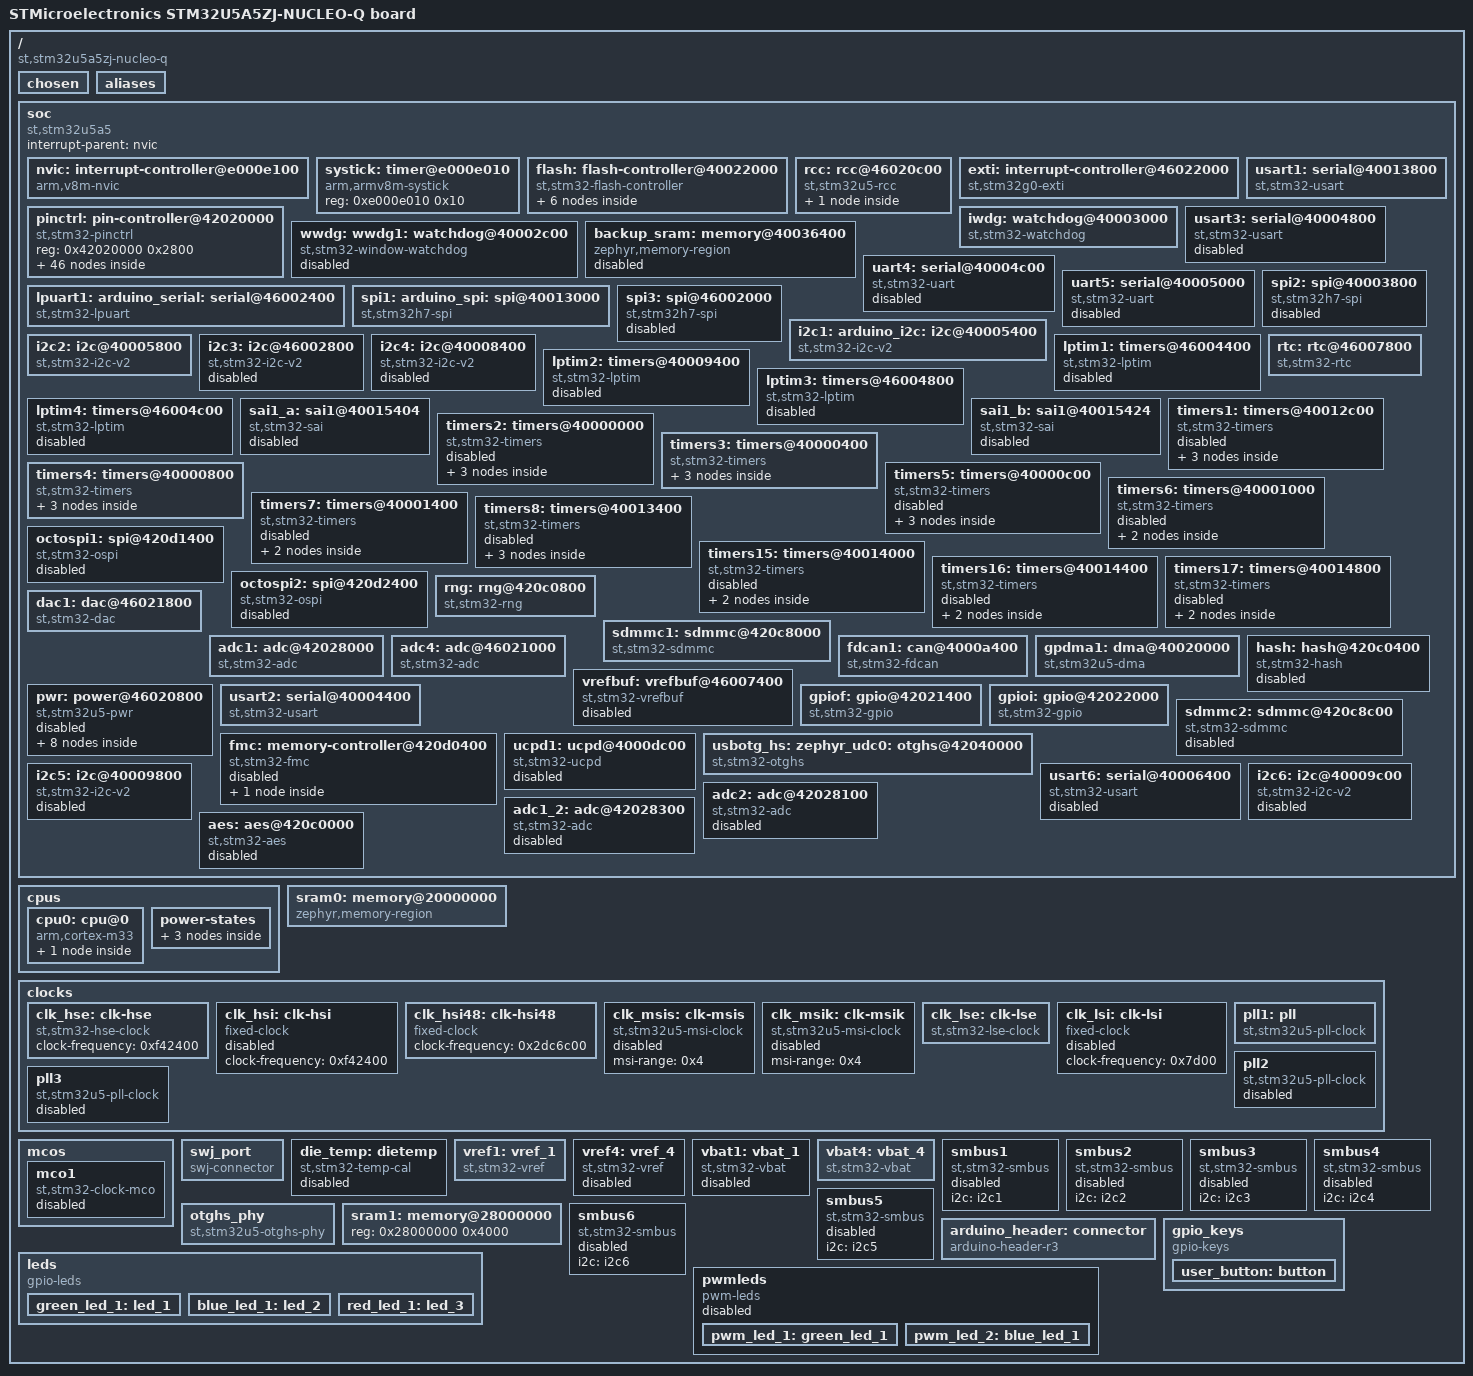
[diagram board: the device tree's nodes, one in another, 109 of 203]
/dts-v1/;

/* node '/' defined in zephyr\dts\common\skeleton.dtsi:9 */
/ {
	model = "STMicroelectronics STM32U5A5ZJ-NUCLEO-Q board"; /* in zephyr\boards\st\nucleo_u5a5zj_q\nucleo_u5a5zj_q.dts:11 */
	compatible = "st,stm32u5a5zj-nucleo-q";                  /* in zephyr\boards\st\nucleo_u5a5zj_q\nucleo_u5a5zj_q.dts:12 */
	#address-cells = < 0x1 >;                                /* in zephyr\boards\st\nucleo_u5a5zj_q\nucleo_u5a5zj_q.dts:14 */
	#size-cells = < 0x1 >;                                   /* in zephyr\boards\st\nucleo_u5a5zj_q\nucleo_u5a5zj_q.dts:15 */

	/* node '/chosen' defined in zephyr\dts\common\skeleton.dtsi:13 */
	chosen {
		zephyr,entropy = &rng;                    /* in zephyr\dts\arm\st\u5\stm32u5.dtsi:28 */
		zephyr,flash-controller = &flash;         /* in zephyr\dts\arm\st\u5\stm32u5.dtsi:29 */
		zephyr,console = &usart1;                 /* in zephyr\boards\st\nucleo_u5a5zj_q\nucleo_u5a5zj_q.dts:18 */
		zephyr,shell-uart = &usart1;              /* in zephyr\boards\st\nucleo_u5a5zj_q\nucleo_u5a5zj_q.dts:19 */
		zephyr,sram = &sram0;                     /* in zephyr\boards\st\nucleo_u5a5zj_q\nucleo_u5a5zj_q.dts:20 */
		zephyr,flash = &flash0;                   /* in zephyr\boards\st\nucleo_u5a5zj_q\nucleo_u5a5zj_q.dts:21 */
		zephyr,canbus = &fdcan1;                  /* in zephyr\boards\st\nucleo_u5a5zj_q\nucleo_u5a5zj_q.dts:22 */
		zephyr,code-partition = &slot0_partition; /* in zephyr\boards\st\nucleo_u5a5zj_q\nucleo_u5a5zj_q.dts:23 */
	};

	/* node '/aliases' defined in zephyr\dts\common\skeleton.dtsi:15 */
	aliases {
		led0 = &blue_led_1;    /* in zephyr\boards\st\nucleo_u5a5zj_q\nucleo_u5a5zj_q.dts:27 */
		sw0 = &user_button;    /* in zephyr\boards\st\nucleo_u5a5zj_q\nucleo_u5a5zj_q.dts:28 */
		pwm-led0 = &pwm_led_1; /* in zephyr\boards\st\nucleo_u5a5zj_q\nucleo_u5a5zj_q.dts:29 */
		pwm-led1 = &pwm_led_2; /* in zephyr\boards\st\nucleo_u5a5zj_q\nucleo_u5a5zj_q.dts:30 */
		watchdog0 = &iwdg;     /* in zephyr\boards\st\nucleo_u5a5zj_q\nucleo_u5a5zj_q.dts:31 */
		volt-sensor0 = &vref1; /* in zephyr\boards\st\nucleo_u5a5zj_q\nucleo_u5a5zj_q.dts:32 */
		volt-sensor1 = &vbat4; /* in zephyr\boards\st\nucleo_u5a5zj_q\nucleo_u5a5zj_q.dts:33 */
	};

	/* node '/soc' defined in zephyr\dts\arm\armv8-m.dtsi:6 */
	soc {
		#address-cells = < 0x1 >;     /* in zephyr\dts\arm\armv8-m.dtsi:7 */
		#size-cells = < 0x1 >;        /* in zephyr\dts\arm\armv8-m.dtsi:8 */
		interrupt-parent = < &nvic >; /* in zephyr\dts\arm\armv8-m.dtsi:10 */
		ranges;                       /* in zephyr\dts\arm\armv8-m.dtsi:11 */
		compatible = "st,stm32u5a5",
		             "st,stm32u5",
		             "simple-bus";    /* in zephyr\dts\arm\st\u5\stm32u5a5.dtsi:13 */

		/* node '/soc/interrupt-controller@e000e100' defined in zephyr\dts\arm\armv8-m.dtsi:13 */
		nvic: interrupt-controller@e000e100 {
			#address-cells = < 0x1 >;            /* in zephyr\dts\arm\armv8-m.dtsi:14 */
			compatible = "arm,v8m-nvic";         /* in zephyr\dts\arm\armv8-m.dtsi:15 */
			reg = < 0xe000e100 0xc00 >;          /* in zephyr\dts\arm\armv8-m.dtsi:16 */
			interrupt-controller;                /* in zephyr\dts\arm\armv8-m.dtsi:17 */
			#interrupt-cells = < 0x2 >;          /* in zephyr\dts\arm\armv8-m.dtsi:18 */
			arm,num-irq-priority-bits = < 0x4 >; /* in zephyr\dts\arm\st\u5\stm32u5.dtsi:1102 */
			phandle = < 0x1 >;                   /* in zephyr\dts\arm\armv8-m.dtsi:10 */
		};

		/* node '/soc/timer@e000e010' defined in zephyr\dts\arm\armv8-m.dtsi:21 */
		systick: timer@e000e010 {
			compatible = "arm,armv8m-systick"; /* in zephyr\dts\arm\armv8-m.dtsi:22 */
			reg = < 0xe000e010 0x10 >;         /* in zephyr\dts\arm\armv8-m.dtsi:23 */
		};

		/* node '/soc/flash-controller@40022000' defined in zephyr\dts\arm\st\u5\stm32u5.dtsi:164 */
		flash: flash-controller@40022000 {
			compatible = "st,stm32-flash-controller",
			             "st,stm32l5-flash-controller"; /* in zephyr\dts\arm\st\u5\stm32u5.dtsi:165 */
			reg = < 0x40022000 0x400 >;                 /* in zephyr\dts\arm\st\u5\stm32u5.dtsi:166 */
			interrupts = < 0x6 0x0 >;                   /* in zephyr\dts\arm\st\u5\stm32u5.dtsi:167 */
			#address-cells = < 0x1 >;                   /* in zephyr\dts\arm\st\u5\stm32u5.dtsi:169 */
			#size-cells = < 0x1 >;                      /* in zephyr\dts\arm\st\u5\stm32u5.dtsi:170 */

			/* node '/soc/flash-controller@40022000/flash@8000000' defined in zephyr\dts\arm\st\u5\stm32u5.dtsi:172 */
			flash0: flash@8000000 {
				compatible = "st,stm32-nv-flash",
				             "soc-nv-flash";      /* in zephyr\dts\arm\st\u5\stm32u5.dtsi:173 */
				write-block-size = < 0x10 >;      /* in zephyr\dts\arm\st\u5\stm32u5.dtsi:175 */
				erase-block-size = < 0x2000 >;    /* in zephyr\dts\arm\st\u5\stm32u5.dtsi:176 */
				max-erase-time = < 0x5 >;         /* in zephyr\dts\arm\st\u5\stm32u5.dtsi:178 */
				reg = < 0x8000000 0x400000 >;     /* in zephyr\dts\arm\st\u5\stm32u5a5Xj.dtsi:14 */

				/* node '/soc/flash-controller@40022000/flash@8000000/partitions' defined in zephyr\boards\st\nucleo_u5a5zj_q\nucleo_u5a5zj_q.dts:38 */
				partitions {
					compatible = "fixed-partitions"; /* in zephyr\boards\st\nucleo_u5a5zj_q\nucleo_u5a5zj_q.dts:39 */
					#address-cells = < 0x1 >;        /* in zephyr\boards\st\nucleo_u5a5zj_q\nucleo_u5a5zj_q.dts:40 */
					#size-cells = < 0x1 >;           /* in zephyr\boards\st\nucleo_u5a5zj_q\nucleo_u5a5zj_q.dts:41 */

					/* node '/soc/flash-controller@40022000/flash@8000000/partitions/partition@0' defined in zephyr\boards\st\nucleo_u5a5zj_q\nucleo_u5a5zj_q.dts:47 */
					boot_partition: partition@0 {
						label = "mcuboot";     /* in zephyr\boards\st\nucleo_u5a5zj_q\nucleo_u5a5zj_q.dts:48 */
						reg = < 0x0 0x10000 >; /* in zephyr\boards\st\nucleo_u5a5zj_q\nucleo_u5a5zj_q.dts:49 */
					};

					/* node '/soc/flash-controller@40022000/flash@8000000/partitions/partition@10000' defined in zephyr\boards\st\nucleo_u5a5zj_q\nucleo_u5a5zj_q.dts:52 */
					slot0_partition: partition@10000 {
						label = "image-0";          /* in zephyr\boards\st\nucleo_u5a5zj_q\nucleo_u5a5zj_q.dts:53 */
						reg = < 0x10000 0x1e8000 >; /* in zephyr\boards\st\nucleo_u5a5zj_q\nucleo_u5a5zj_q.dts:54 */
					};

					/* node '/soc/flash-controller@40022000/flash@8000000/partitions/partition@1f8000' defined in zephyr\boards\st\nucleo_u5a5zj_q\nucleo_u5a5zj_q.dts:57 */
					slot1_partition: partition@1f8000 {
						label = "image-1";           /* in zephyr\boards\st\nucleo_u5a5zj_q\nucleo_u5a5zj_q.dts:58 */
						reg = < 0x1f8000 0x1ea000 >; /* in zephyr\boards\st\nucleo_u5a5zj_q\nucleo_u5a5zj_q.dts:59 */
					};

					/* node '/soc/flash-controller@40022000/flash@8000000/partitions/partition@3e2000' defined in zephyr\boards\st\nucleo_u5a5zj_q\nucleo_u5a5zj_q.dts:62 */
					storage_partition: partition@3e2000 {
						label = "storage";          /* in zephyr\boards\st\nucleo_u5a5zj_q\nucleo_u5a5zj_q.dts:63 */
						reg = < 0x3e2000 0x1e000 >; /* in zephyr\boards\st\nucleo_u5a5zj_q\nucleo_u5a5zj_q.dts:64 */
					};
				};
			};
		};

		/* node '/soc/rcc@46020c00' defined in zephyr\dts\arm\st\u5\stm32u5.dtsi:182 */
		rcc: rcc@46020c00 {
			compatible = "st,stm32u5-rcc";   /* in zephyr\dts\arm\st\u5\stm32u5.dtsi:183 */
			clocks-controller;               /* in zephyr\dts\arm\st\u5\stm32u5.dtsi:184 */
			#clock-cells = < 0x2 >;          /* in zephyr\dts\arm\st\u5\stm32u5.dtsi:185 */
			reg = < 0x46020c00 0x400 >;      /* in zephyr\dts\arm\st\u5\stm32u5.dtsi:186 */
			clocks = < &pll1 >;              /* in zephyr\boards\st\nucleo_u5a5zj_q\nucleo_u5a5zj_q-common.dtsi:84 */
			clock-frequency = < 0x9896800 >; /* in zephyr\boards\st\nucleo_u5a5zj_q\nucleo_u5a5zj_q-common.dtsi:85 */
			ahb-prescaler = < 0x1 >;         /* in zephyr\boards\st\nucleo_u5a5zj_q\nucleo_u5a5zj_q-common.dtsi:86 */
			apb1-prescaler = < 0x1 >;        /* in zephyr\boards\st\nucleo_u5a5zj_q\nucleo_u5a5zj_q-common.dtsi:87 */
			apb2-prescaler = < 0x1 >;        /* in zephyr\boards\st\nucleo_u5a5zj_q\nucleo_u5a5zj_q-common.dtsi:88 */
			apb3-prescaler = < 0x1 >;        /* in zephyr\boards\st\nucleo_u5a5zj_q\nucleo_u5a5zj_q-common.dtsi:89 */
			phandle = < 0x3 >;               /* in zephyr\dts\arm\st\u5\stm32u5.dtsi:200 */

			/* node '/soc/rcc@46020c00/reset-controller' defined in zephyr\dts\arm\st\u5\stm32u5.dtsi:188 */
			rctl: reset-controller {
				compatible = "st,stm32-rcc-rctl"; /* in zephyr\dts\arm\st\u5\stm32u5.dtsi:189 */
				#reset-cells = < 0x1 >;           /* in zephyr\dts\arm\st\u5\stm32u5.dtsi:190 */
				phandle = < 0x4 >;                /* in zephyr\dts\arm\st\u5\stm32u5.dtsi:307 */
			};
		};

		/* node '/soc/interrupt-controller@46022000' defined in zephyr\dts\arm\st\u5\stm32u5.dtsi:194 */
		exti: interrupt-controller@46022000 {
			compatible = "st,stm32g0-exti",
			             "st,stm32-exti";   /* in zephyr\dts\arm\st\u5\stm32u5.dtsi:195 */
			interrupt-controller;           /* in zephyr\dts\arm\st\u5\stm32u5.dtsi:196 */
			#interrupt-cells = < 0x1 >;     /* in zephyr\dts\arm\st\u5\stm32u5.dtsi:197 */
			#address-cells = < 0x0 >;       /* in zephyr\dts\arm\st\u5\stm32u5.dtsi:198 */
			reg = < 0x46022000 0x400 >;     /* in zephyr\dts\arm\st\u5\stm32u5.dtsi:199 */
			clocks = < &rcc 0xa8 0x2 >;     /* in zephyr\dts\arm\st\u5\stm32u5.dtsi:200 */
			num-lines = < 0x20 >;           /* in zephyr\dts\arm\st\u5\stm32u5.dtsi:201 */
			interrupts = < 0xb 0x0 >,
			             < 0xc 0x0 >,
			             < 0xd 0x0 >,
			             < 0xe 0x0 >,
			             < 0xf 0x0 >,
			             < 0x10 0x0 >,
			             < 0x11 0x0 >,
			             < 0x12 0x0 >,
			             < 0x13 0x0 >,
			             < 0x14 0x0 >,
			             < 0x15 0x0 >,
			             < 0x16 0x0 >,
			             < 0x17 0x0 >,
			             < 0x18 0x0 >,
			             < 0x19 0x0 >,
			             < 0x1a 0x0 >;      /* in zephyr\dts\arm\st\u5\stm32u5.dtsi:202 */
			interrupt-names = "line0",
			                  "line1",
			                  "line2",
			                  "line3",
			                  "line4",
			                  "line5",
			                  "line6",
			                  "line7",
			                  "line8",
			                  "line9",
			                  "line10",
			                  "line11",
			                  "line12",
			                  "line13",
			                  "line14",
			                  "line15";     /* in zephyr\dts\arm\st\u5\stm32u5.dtsi:206 */
			line-ranges = < 0x0 0x1 >,
			              < 0x1 0x1 >,
			              < 0x2 0x1 >,
			              < 0x3 0x1 >,
			              < 0x4 0x1 >,
			              < 0x5 0x1 >,
			              < 0x6 0x1 >,
			              < 0x7 0x1 >,
			              < 0x8 0x1 >,
			              < 0x9 0x1 >,
			              < 0xa 0x1 >,
			              < 0xb 0x1 >,
			              < 0xc 0x1 >,
			              < 0xd 0x1 >,
			              < 0xe 0x1 >,
			              < 0xf 0x1 >;      /* in zephyr\dts\arm\st\u5\stm32u5.dtsi:210 */
		};

		/* node '/soc/pin-controller@42020000' defined in zephyr\dts\arm\st\u5\stm32u5.dtsi:216 */
		pinctrl: pin-controller@42020000 {
			compatible = "st,stm32-pinctrl"; /* in zephyr\dts\arm\st\u5\stm32u595.dtsi:26 */
			#address-cells = < 0x1 >;        /* in zephyr\dts\arm\st\u5\stm32u595.dtsi:27 */
			#size-cells = < 0x1 >;           /* in zephyr\dts\arm\st\u5\stm32u595.dtsi:28 */
			reg = < 0x42020000 0x2800 >;     /* in zephyr\dts\arm\st\u5\stm32u595.dtsi:29 */

			/* node '/soc/pin-controller@42020000/gpio@42020000' defined in zephyr\dts\arm\st\u5\stm32u5.dtsi:222 */
			gpioa: gpio@42020000 {
				compatible = "st,stm32-gpio"; /* in zephyr\dts\arm\st\u5\stm32u5.dtsi:223 */
				gpio-controller;              /* in zephyr\dts\arm\st\u5\stm32u5.dtsi:224 */
				#gpio-cells = < 0x2 >;        /* in zephyr\dts\arm\st\u5\stm32u5.dtsi:225 */
				reg = < 0x42020000 0x400 >;   /* in zephyr\dts\arm\st\u5\stm32u5.dtsi:226 */
				clocks = < &rcc 0x8c 0x1 >;   /* in zephyr\dts\arm\st\u5\stm32u5.dtsi:227 */
				phandle = < 0x1f >;           /* in zephyr\dts\arm\st\u5\stm32u5.dtsi:959 */
			};

			/* node '/soc/pin-controller@42020000/gpio@42020400' defined in zephyr\dts\arm\st\u5\stm32u5.dtsi:230 */
			gpiob: gpio@42020400 {
				compatible = "st,stm32-gpio"; /* in zephyr\dts\arm\st\u5\stm32u5.dtsi:231 */
				gpio-controller;              /* in zephyr\dts\arm\st\u5\stm32u5.dtsi:232 */
				#gpio-cells = < 0x2 >;        /* in zephyr\dts\arm\st\u5\stm32u5.dtsi:233 */
				reg = < 0x42020400 0x400 >;   /* in zephyr\dts\arm\st\u5\stm32u5.dtsi:234 */
				clocks = < &rcc 0x8c 0x2 >;   /* in zephyr\dts\arm\st\u5\stm32u5.dtsi:235 */
				phandle = < 0x20 >;           /* in zephyr\dts\arm\st\u5\stm32u5.dtsi:959 */
			};

			/* node '/soc/pin-controller@42020000/gpio@42020800' defined in zephyr\dts\arm\st\u5\stm32u5.dtsi:238 */
			gpioc: gpio@42020800 {
				compatible = "st,stm32-gpio"; /* in zephyr\dts\arm\st\u5\stm32u5.dtsi:239 */
				gpio-controller;              /* in zephyr\dts\arm\st\u5\stm32u5.dtsi:240 */
				#gpio-cells = < 0x2 >;        /* in zephyr\dts\arm\st\u5\stm32u5.dtsi:241 */
				reg = < 0x42020800 0x400 >;   /* in zephyr\dts\arm\st\u5\stm32u5.dtsi:242 */
				clocks = < &rcc 0x8c 0x4 >;   /* in zephyr\dts\arm\st\u5\stm32u5.dtsi:243 */
				phandle = < 0x22 >;           /* in zephyr\dts\arm\st\u5\stm32u5.dtsi:966 */
			};

			/* node '/soc/pin-controller@42020000/gpio@42020c00' defined in zephyr\dts\arm\st\u5\stm32u5.dtsi:246 */
			gpiod: gpio@42020c00 {
				compatible = "st,stm32-gpio"; /* in zephyr\dts\arm\st\u5\stm32u5.dtsi:247 */
				gpio-controller;              /* in zephyr\dts\arm\st\u5\stm32u5.dtsi:248 */
				#gpio-cells = < 0x2 >;        /* in zephyr\dts\arm\st\u5\stm32u5.dtsi:249 */
				reg = < 0x42020c00 0x400 >;   /* in zephyr\dts\arm\st\u5\stm32u5.dtsi:250 */
				clocks = < &rcc 0x8c 0x8 >;   /* in zephyr\dts\arm\st\u5\stm32u5.dtsi:251 */
				phandle = < 0xc >;            /* in zephyr\boards\st\nucleo_u5a5zj_q\nucleo_u5a5zj_q-common.dtsi:123 */
			};

			/* node '/soc/pin-controller@42020000/gpio@42021000' defined in zephyr\dts\arm\st\u5\stm32u5.dtsi:254 */
			gpioe: gpio@42021000 {
				compatible = "st,stm32-gpio"; /* in zephyr\dts\arm\st\u5\stm32u5.dtsi:255 */
				gpio-controller;              /* in zephyr\dts\arm\st\u5\stm32u5.dtsi:256 */
				#gpio-cells = < 0x2 >;        /* in zephyr\dts\arm\st\u5\stm32u5.dtsi:257 */
				reg = < 0x42021000 0x400 >;   /* in zephyr\dts\arm\st\u5\stm32u5.dtsi:258 */
				clocks = < &rcc 0x8c 0x10 >;  /* in zephyr\dts\arm\st\u5\stm32u5.dtsi:259 */
				phandle = < 0x21 >;           /* in zephyr\dts\arm\st\u5\stm32u5.dtsi:959 */
			};

			/* node '/soc/pin-controller@42020000/gpio@42021800' defined in zephyr\dts\arm\st\u5\stm32u5.dtsi:262 */
			gpiog: gpio@42021800 {
				compatible = "st,stm32-gpio"; /* in zephyr\dts\arm\st\u5\stm32u5.dtsi:263 */
				gpio-controller;              /* in zephyr\dts\arm\st\u5\stm32u5.dtsi:264 */
				#gpio-cells = < 0x2 >;        /* in zephyr\dts\arm\st\u5\stm32u5.dtsi:265 */
				reg = < 0x42021800 0x400 >;   /* in zephyr\dts\arm\st\u5\stm32u5.dtsi:266 */
				clocks = < &rcc 0x8c 0x40 >;  /* in zephyr\dts\arm\st\u5\stm32u5.dtsi:267 */
				phandle = < 0x3f >;           /* in zephyr\boards\st\nucleo_u5a5zj_q\arduino_r3_connector.dtsi:15 */
			};

			/* node '/soc/pin-controller@42020000/gpio@42021c00' defined in zephyr\dts\arm\st\u5\stm32u5.dtsi:270 */
			gpioh: gpio@42021c00 {
				compatible = "st,stm32-gpio"; /* in zephyr\dts\arm\st\u5\stm32u5.dtsi:271 */
				gpio-controller;              /* in zephyr\dts\arm\st\u5\stm32u5.dtsi:272 */
				#gpio-cells = < 0x2 >;        /* in zephyr\dts\arm\st\u5\stm32u5.dtsi:273 */
				reg = < 0x42021c00 0x400 >;   /* in zephyr\dts\arm\st\u5\stm32u5.dtsi:274 */
				clocks = < &rcc 0x8c 0x80 >;  /* in zephyr\dts\arm\st\u5\stm32u5.dtsi:275 */
			};

			/* node '/soc/pin-controller@42020000/gpio@42022400' defined in zephyr\dts\arm\st\u5\stm32u595.dtsi:31 */
			gpioj: gpio@42022400 {
				compatible = "st,stm32-gpio"; /* in zephyr\dts\arm\st\u5\stm32u595.dtsi:32 */
				gpio-controller;              /* in zephyr\dts\arm\st\u5\stm32u595.dtsi:33 */
				#gpio-cells = < 0x2 >;        /* in zephyr\dts\arm\st\u5\stm32u595.dtsi:34 */
				reg = < 0x42022400 0x400 >;   /* in zephyr\dts\arm\st\u5\stm32u595.dtsi:35 */
				clocks = < &rcc 0x8c 0x200 >; /* in zephyr\dts\arm\st\u5\stm32u595.dtsi:36 */
			};

			/* node '/soc/pin-controller@42020000/adc1_in1_pc0' defined in modules\hal\stm32\dts\st\u5\stm32u5a5zjtxq-pinctrl.dtsi:59 */
			adc1_in1_pc0: adc1_in1_pc0 {
				pinmux = < 0x410 >; /* in modules\hal\stm32\dts\st\u5\stm32u5a5zjtxq-pinctrl.dtsi:60 */
				phandle = < 0x1b >; /* in zephyr\boards\st\nucleo_u5a5zj_q\nucleo_u5a5zj_q-common.dtsi:134 */
			};

			/* node '/soc/pin-controller@42020000/adc4_in18_pb0' defined in modules\hal\stm32\dts\st\u5\stm32u5a5zjtxq-pinctrl.dtsi:151 */
			adc4_in18_pb0: adc4_in18_pb0 {
				pinmux = < 0x210 >; /* in modules\hal\stm32\dts\st\u5\stm32u5a5zjtxq-pinctrl.dtsi:152 */
				phandle = < 0x1c >; /* in zephyr\boards\st\nucleo_u5a5zj_q\nucleo_u5a5zj_q-common.dtsi:142 */
			};

			/* node '/soc/pin-controller@42020000/analog_pa13' defined in modules\hal\stm32\dts\st\u5\stm32u5a5zjtxq-pinctrl.dtsi:257 */
			analog_pa13: analog_pa13 {
				pinmux = < 0x1b0 >; /* in modules\hal\stm32\dts\st\u5\stm32u5a5zjtxq-pinctrl.dtsi:258 */
				phandle = < 0x32 >; /* in zephyr\dts\arm\st\u5\stm32u5.dtsi:1019 */
			};

			/* node '/soc/pin-controller@42020000/analog_pa14' defined in modules\hal\stm32\dts\st\u5\stm32u5a5zjtxq-pinctrl.dtsi:261 */
			analog_pa14: analog_pa14 {
				pinmux = < 0x1d0 >; /* in modules\hal\stm32\dts\st\u5\stm32u5a5zjtxq-pinctrl.dtsi:262 */
				phandle = < 0x33 >; /* in zephyr\dts\arm\st\u5\stm32u5.dtsi:1019 */
			};

			/* node '/soc/pin-controller@42020000/analog_pa15' defined in modules\hal\stm32\dts\st\u5\stm32u5a5zjtxq-pinctrl.dtsi:265 */
			analog_pa15: analog_pa15 {
				pinmux = < 0x1f0 >; /* in modules\hal\stm32\dts\st\u5\stm32u5a5zjtxq-pinctrl.dtsi:266 */
				phandle = < 0x34 >; /* in zephyr\dts\arm\st\u5\stm32u5.dtsi:1019 */
			};

			/* node '/soc/pin-controller@42020000/analog_pb3' defined in modules\hal\stm32\dts\st\u5\stm32u5a5zjtxq-pinctrl.dtsi:281 */
			analog_pb3: analog_pb3 {
				pinmux = < 0x270 >; /* in modules\hal\stm32\dts\st\u5\stm32u5a5zjtxq-pinctrl.dtsi:282 */
				phandle = < 0x35 >; /* in zephyr\dts\arm\st\u5\stm32u5.dtsi:1019 */
			};

			/* node '/soc/pin-controller@42020000/analog_pb4' defined in modules\hal\stm32\dts\st\u5\stm32u5a5zjtxq-pinctrl.dtsi:285 */
			analog_pb4: analog_pb4 {
				pinmux = < 0x290 >; /* in modules\hal\stm32\dts\st\u5\stm32u5a5zjtxq-pinctrl.dtsi:286 */
				phandle = < 0x36 >; /* in zephyr\dts\arm\st\u5\stm32u5.dtsi:1019 */
			};

			/* node '/soc/pin-controller@42020000/dac1_out1_pa4' defined in modules\hal\stm32\dts\st\u5\stm32u5a5zjtxq-pinctrl.dtsi:699 */
			dac1_out1_pa4: dac1_out1_pa4 {
				pinmux = < 0x90 >;  /* in modules\hal\stm32\dts\st\u5\stm32u5a5zjtxq-pinctrl.dtsi:700 */
				phandle = < 0x1a >; /* in zephyr\boards\st\nucleo_u5a5zj_q\nucleo_u5a5zj_q-common.dtsi:128 */
			};

			/* node '/soc/pin-controller@42020000/fdcan1_rx_pd0' defined in modules\hal\stm32\dts\st\u5\stm32u5a5zjtxq-pinctrl.dtsi:879 */
			fdcan1_rx_pd0: fdcan1_rx_pd0 {
				pinmux = < 0x609 >; /* in modules\hal\stm32\dts\st\u5\stm32u5a5zjtxq-pinctrl.dtsi:880 */
				phandle = < 0x1d >; /* in zephyr\boards\st\nucleo_u5a5zj_q\nucleo_u5a5zj_q-common.dtsi:182 */
			};

			/* node '/soc/pin-controller@42020000/fdcan1_tx_pd1' defined in modules\hal\stm32\dts\st\u5\stm32u5a5zjtxq-pinctrl.dtsi:897 */
			fdcan1_tx_pd1: fdcan1_tx_pd1 {
				pinmux = < 0x629 >; /* in modules\hal\stm32\dts\st\u5\stm32u5a5zjtxq-pinctrl.dtsi:898 */
				phandle = < 0x1e >; /* in zephyr\boards\st\nucleo_u5a5zj_q\nucleo_u5a5zj_q-common.dtsi:182 */
			};

			/* node '/soc/pin-controller@42020000/i2c1_scl_pb8' defined in modules\hal\stm32\dts\st\u5\stm32u5a5zjtxq-pinctrl.dtsi:1269 */
			i2c1_scl_pb8: i2c1_scl_pb8 {
				pinmux = < 0x304 >; /* in modules\hal\stm32\dts\st\u5\stm32u5a5zjtxq-pinctrl.dtsi:1270 */
				bias-pull-up;       /* in modules\hal\stm32\dts\st\u5\stm32u5a5zjtxq-pinctrl.dtsi:1271 */
				drive-open-drain;   /* in modules\hal\stm32\dts\st\u5\stm32u5a5zjtxq-pinctrl.dtsi:1272 */
				phandle = < 0xd >;  /* in zephyr\boards\st\nucleo_u5a5zj_q\nucleo_u5a5zj_q-common.dtsi:107 */
			};

			/* node '/soc/pin-controller@42020000/i2c2_scl_pf1' defined in modules\hal\stm32\dts\st\u5\stm32u5a5zjtxq-pinctrl.dtsi:1293 */
			i2c2_scl_pf1: i2c2_scl_pf1 {
				pinmux = < 0xa24 >; /* in modules\hal\stm32\dts\st\u5\stm32u5a5zjtxq-pinctrl.dtsi:1294 */
				bias-pull-up;       /* in modules\hal\stm32\dts\st\u5\stm32u5a5zjtxq-pinctrl.dtsi:1295 */
				drive-open-drain;   /* in modules\hal\stm32\dts\st\u5\stm32u5a5zjtxq-pinctrl.dtsi:1296 */
				phandle = < 0xf >;  /* in zephyr\boards\st\nucleo_u5a5zj_q\nucleo_u5a5zj_q-common.dtsi:114 */
			};

			/* node '/soc/pin-controller@42020000/i2c1_sda_pb9' defined in modules\hal\stm32\dts\st\u5\stm32u5a5zjtxq-pinctrl.dtsi:1373 */
			i2c1_sda_pb9: i2c1_sda_pb9 {
				pinmux = < 0x324 >; /* in modules\hal\stm32\dts\st\u5\stm32u5a5zjtxq-pinctrl.dtsi:1374 */
				bias-pull-up;       /* in modules\hal\stm32\dts\st\u5\stm32u5a5zjtxq-pinctrl.dtsi:1375 */
				drive-open-drain;   /* in modules\hal\stm32\dts\st\u5\stm32u5a5zjtxq-pinctrl.dtsi:1376 */
				phandle = < 0xe >;  /* in zephyr\boards\st\nucleo_u5a5zj_q\nucleo_u5a5zj_q-common.dtsi:107 */
			};

			/* node '/soc/pin-controller@42020000/i2c2_sda_pf0' defined in modules\hal\stm32\dts\st\u5\stm32u5a5zjtxq-pinctrl.dtsi:1397 */
			i2c2_sda_pf0: i2c2_sda_pf0 {
				pinmux = < 0xa04 >; /* in modules\hal\stm32\dts\st\u5\stm32u5a5zjtxq-pinctrl.dtsi:1398 */
				bias-pull-up;       /* in modules\hal\stm32\dts\st\u5\stm32u5a5zjtxq-pinctrl.dtsi:1399 */
				drive-open-drain;   /* in modules\hal\stm32\dts\st\u5\stm32u5a5zjtxq-pinctrl.dtsi:1400 */
				phandle = < 0x10 >; /* in zephyr\boards\st\nucleo_u5a5zj_q\nucleo_u5a5zj_q-common.dtsi:114 */
			};

			/* node '/soc/pin-controller@42020000/debug_jtms_swdio_pa13' defined in modules\hal\stm32\dts\st\u5\stm32u5a5zjtxq-pinctrl.dtsi:1532 */
			debug_jtms_swdio_pa13: debug_jtms_swdio_pa13 {
				pinmux = < 0x1a0 >; /* in modules\hal\stm32\dts\st\u5\stm32u5a5zjtxq-pinctrl.dtsi:1533 */
				phandle = < 0x2d >; /* in zephyr\dts\arm\st\u5\stm32u5.dtsi:1016 */
			};

			/* node '/soc/pin-controller@42020000/debug_jtck_swclk_pa14' defined in modules\hal\stm32\dts\st\u5\stm32u5a5zjtxq-pinctrl.dtsi:1536 */
			debug_jtck_swclk_pa14: debug_jtck_swclk_pa14 {
				pinmux = < 0x1c0 >; /* in modules\hal\stm32\dts\st\u5\stm32u5a5zjtxq-pinctrl.dtsi:1537 */
				phandle = < 0x2e >; /* in zephyr\dts\arm\st\u5\stm32u5.dtsi:1016 */
			};

			/* node '/soc/pin-controller@42020000/debug_jtdi_pa15' defined in modules\hal\stm32\dts\st\u5\stm32u5a5zjtxq-pinctrl.dtsi:1540 */
			debug_jtdi_pa15: debug_jtdi_pa15 {
				pinmux = < 0x1e0 >; /* in modules\hal\stm32\dts\st\u5\stm32u5a5zjtxq-pinctrl.dtsi:1541 */
				phandle = < 0x2f >; /* in zephyr\dts\arm\st\u5\stm32u5.dtsi:1016 */
			};

			/* node '/soc/pin-controller@42020000/debug_jtdo_swo_pb3' defined in modules\hal\stm32\dts\st\u5\stm32u5a5zjtxq-pinctrl.dtsi:1544 */
			debug_jtdo_swo_pb3: debug_jtdo_swo_pb3 {
				pinmux = < 0x260 >; /* in modules\hal\stm32\dts\st\u5\stm32u5a5zjtxq-pinctrl.dtsi:1545 */
				phandle = < 0x30 >; /* in zephyr\dts\arm\st\u5\stm32u5.dtsi:1016 */
			};

			/* node '/soc/pin-controller@42020000/debug_jtrst_pb4' defined in modules\hal\stm32\dts\st\u5\stm32u5a5zjtxq-pinctrl.dtsi:1548 */
			debug_jtrst_pb4: debug_jtrst_pb4 {
				pinmux = < 0x280 >; /* in modules\hal\stm32\dts\st\u5\stm32u5a5zjtxq-pinctrl.dtsi:1549 */
				phandle = < 0x31 >; /* in zephyr\dts\arm\st\u5\stm32u5.dtsi:1016 */
			};

			/* node '/soc/pin-controller@42020000/sdmmc1_d0_pc8' defined in modules\hal\stm32\dts\st\u5\stm32u5a5zjtxq-pinctrl.dtsi:2175 */
			sdmmc1_d0_pc8: sdmmc1_d0_pc8 {
				pinmux = < 0x50c >;            /* in modules\hal\stm32\dts\st\u5\stm32u5a5zjtxq-pinctrl.dtsi:2176 */
				bias-pull-up;                  /* in modules\hal\stm32\dts\st\u5\stm32u5a5zjtxq-pinctrl.dtsi:2177 */
				slew-rate = "very-high-speed"; /* in modules\hal\stm32\dts\st\u5\stm32u5a5zjtxq-pinctrl.dtsi:2178 */
				phandle = < 0x14 >;            /* in boards\nucleo_u5a5zj_q.overlay:19 */
			};

			/* node '/soc/pin-controller@42020000/sdmmc1_d1_pc9' defined in modules\hal\stm32\dts\st\u5\stm32u5a5zjtxq-pinctrl.dtsi:2181 */
			sdmmc1_d1_pc9: sdmmc1_d1_pc9 {
				pinmux = < 0x52c >;            /* in modules\hal\stm32\dts\st\u5\stm32u5a5zjtxq-pinctrl.dtsi:2182 */
				bias-pull-up;                  /* in modules\hal\stm32\dts\st\u5\stm32u5a5zjtxq-pinctrl.dtsi:2183 */
				slew-rate = "very-high-speed"; /* in modules\hal\stm32\dts\st\u5\stm32u5a5zjtxq-pinctrl.dtsi:2184 */
				phandle = < 0x15 >;            /* in boards\nucleo_u5a5zj_q.overlay:19 */
			};

			/* node '/soc/pin-controller@42020000/sdmmc1_d2_pc10' defined in modules\hal\stm32\dts\st\u5\stm32u5a5zjtxq-pinctrl.dtsi:2187 */
			sdmmc1_d2_pc10: sdmmc1_d2_pc10 {
				pinmux = < 0x54c >;            /* in modules\hal\stm32\dts\st\u5\stm32u5a5zjtxq-pinctrl.dtsi:2188 */
				bias-pull-up;                  /* in modules\hal\stm32\dts\st\u5\stm32u5a5zjtxq-pinctrl.dtsi:2189 */
				slew-rate = "very-high-speed"; /* in modules\hal\stm32\dts\st\u5\stm32u5a5zjtxq-pinctrl.dtsi:2190 */
				phandle = < 0x16 >;            /* in boards\nucleo_u5a5zj_q.overlay:19 */
			};

			/* node '/soc/pin-controller@42020000/sdmmc1_d3_pc11' defined in modules\hal\stm32\dts\st\u5\stm32u5a5zjtxq-pinctrl.dtsi:2193 */
			sdmmc1_d3_pc11: sdmmc1_d3_pc11 {
				pinmux = < 0x56c >;            /* in modules\hal\stm32\dts\st\u5\stm32u5a5zjtxq-pinctrl.dtsi:2194 */
				bias-pull-up;                  /* in modules\hal\stm32\dts\st\u5\stm32u5a5zjtxq-pinctrl.dtsi:2195 */
				slew-rate = "very-high-speed"; /* in modules\hal\stm32\dts\st\u5\stm32u5a5zjtxq-pinctrl.dtsi:2196 */
				phandle = < 0x17 >;            /* in boards\nucleo_u5a5zj_q.overlay:19 */
			};

			/* node '/soc/pin-controller@42020000/sdmmc1_ck_pc12' defined in modules\hal\stm32\dts\st\u5\stm32u5a5zjtxq-pinctrl.dtsi:2199 */
			sdmmc1_ck_pc12: sdmmc1_ck_pc12 {
				pinmux = < 0x58c >;            /* in modules\hal\stm32\dts\st\u5\stm32u5a5zjtxq-pinctrl.dtsi:2200 */
				bias-pull-up;                  /* in modules\hal\stm32\dts\st\u5\stm32u5a5zjtxq-pinctrl.dtsi:2201 */
				slew-rate = "very-high-speed"; /* in modules\hal\stm32\dts\st\u5\stm32u5a5zjtxq-pinctrl.dtsi:2202 */
				phandle = < 0x18 >;            /* in boards\nucleo_u5a5zj_q.overlay:19 */
			};

			/* node '/soc/pin-controller@42020000/sdmmc1_cmd_pd2' defined in modules\hal\stm32\dts\st\u5\stm32u5a5zjtxq-pinctrl.dtsi:2205 */
			sdmmc1_cmd_pd2: sdmmc1_cmd_pd2 {
				pinmux = < 0x64c >;            /* in modules\hal\stm32\dts\st\u5\stm32u5a5zjtxq-pinctrl.dtsi:2206 */
				bias-pull-up;                  /* in modules\hal\stm32\dts\st\u5\stm32u5a5zjtxq-pinctrl.dtsi:2207 */
				slew-rate = "very-high-speed"; /* in modules\hal\stm32\dts\st\u5\stm32u5a5zjtxq-pinctrl.dtsi:2208 */
				phandle = < 0x19 >;            /* in boards\nucleo_u5a5zj_q.overlay:19 */
			};

			/* node '/soc/pin-controller@42020000/spi1_miso_pa6' defined in modules\hal\stm32\dts\st\u5\stm32u5a5zjtxq-pinctrl.dtsi:2285 */
			spi1_miso_pa6: spi1_miso_pa6 {
				pinmux = < 0xc5 >; /* in modules\hal\stm32\dts\st\u5\stm32u5a5zjtxq-pinctrl.dtsi:2286 */
				bias-pull-down;    /* in modules\hal\stm32\dts\st\u5\stm32u5a5zjtxq-pinctrl.dtsi:2287 */
				phandle = < 0xa >; /* in zephyr\boards\st\nucleo_u5a5zj_q\nucleo_u5a5zj_q-common.dtsi:121 */
			};

			/* node '/soc/pin-controller@42020000/spi1_mosi_pa7' defined in modules\hal\stm32\dts\st\u5\stm32u5a5zjtxq-pinctrl.dtsi:2342 */
			spi1_mosi_pa7: spi1_mosi_pa7 {
				pinmux = < 0xe5 >; /* in modules\hal\stm32\dts\st\u5\stm32u5a5zjtxq-pinctrl.dtsi:2343 */
				bias-pull-down;    /* in modules\hal\stm32\dts\st\u5\stm32u5a5zjtxq-pinctrl.dtsi:2344 */
				phandle = < 0xb >; /* in zephyr\boards\st\nucleo_u5a5zj_q\nucleo_u5a5zj_q-common.dtsi:121 */
			};

			/* node '/soc/pin-controller@42020000/spi1_sck_pa5' defined in modules\hal\stm32\dts\st\u5\stm32u5a5zjtxq-pinctrl.dtsi:2462 */
			spi1_sck_pa5: spi1_sck_pa5 {
				pinmux = < 0xa5 >;             /* in modules\hal\stm32\dts\st\u5\stm32u5a5zjtxq-pinctrl.dtsi:2463 */
				bias-pull-down;                /* in modules\hal\stm32\dts\st\u5\stm32u5a5zjtxq-pinctrl.dtsi:2464 */
				slew-rate = "very-high-speed"; /* in modules\hal\stm32\dts\st\u5\stm32u5a5zjtxq-pinctrl.dtsi:2465 */
				phandle = < 0x9 >;             /* in zephyr\boards\st\nucleo_u5a5zj_q\nucleo_u5a5zj_q-common.dtsi:121 */
			};

			/* node '/soc/pin-controller@42020000/tim3_ch2_pc7' defined in modules\hal\stm32\dts\st\u5\stm32u5a5zjtxq-pinctrl.dtsi:2722 */
			tim3_ch2_pc7: tim3_ch2_pc7 {
				pinmux = < 0x4e2 >; /* in modules\hal\stm32\dts\st\u5\stm32u5a5zjtxq-pinctrl.dtsi:2723 */
				phandle = < 0x12 >; /* in zephyr\boards\st\nucleo_u5a5zj_q\nucleo_u5a5zj_q-common.dtsi:154 */
			};

			/* node '/soc/pin-controller@42020000/tim4_ch2_pb7' defined in modules\hal\stm32\dts\st\u5\stm32u5a5zjtxq-pinctrl.dtsi:2754 */
			tim4_ch2_pb7: tim4_ch2_pb7 {
				pinmux = < 0x2e2 >; /* in modules\hal\stm32\dts\st\u5\stm32u5a5zjtxq-pinctrl.dtsi:2755 */
				phandle = < 0x13 >; /* in zephyr\boards\st\nucleo_u5a5zj_q\nucleo_u5a5zj_q-common.dtsi:165 */
			};

			/* node '/soc/pin-controller@42020000/usart1_rx_pa10' defined in modules\hal\stm32\dts\st\u5\stm32u5a5zjtxq-pinctrl.dtsi:3322 */
			usart1_rx_pa10: usart1_rx_pa10 {
				pinmux = < 0x147 >; /* in modules\hal\stm32\dts\st\u5\stm32u5a5zjtxq-pinctrl.dtsi:3323 */
				phandle = < 0x6 >;  /* in zephyr\boards\st\nucleo_u5a5zj_q\nucleo_u5a5zj_q.dts:70 */
			};

			/* node '/soc/pin-controller@42020000/lpuart1_rx_pg8' defined in modules\hal\stm32\dts\st\u5\stm32u5a5zjtxq-pinctrl.dtsi:3338 */
			lpuart1_rx_pg8: lpuart1_rx_pg8 {
				pinmux = < 0xd08 >; /* in modules\hal\stm32\dts\st\u5\stm32u5a5zjtxq-pinctrl.dtsi:3339 */
				phandle = < 0x8 >;  /* in zephyr\boards\st\nucleo_u5a5zj_q\nucleo_u5a5zj_q-common.dtsi:93 */
			};

			/* node '/soc/pin-controller@42020000/usart2_rx_pd6' defined in modules\hal\stm32\dts\st\u5\stm32u5a5zjtxq-pinctrl.dtsi:3354 */
			usart2_rx_pd6: usart2_rx_pd6 {
				pinmux = < 0x6c7 >; /* in modules\hal\stm32\dts\st\u5\stm32u5a5zjtxq-pinctrl.dtsi:3355 */
				phandle = < 0x25 >; /* in zephyr\boards\st\nucleo_u5a5zj_q\nucleo_u5a5zj_q-common.dtsi:100 */
			};

			/* node '/soc/pin-controller@42020000/usart1_tx_pa9' defined in modules\hal\stm32\dts\st\u5\stm32u5a5zjtxq-pinctrl.dtsi:3413 */
			usart1_tx_pa9: usart1_tx_pa9 {
				pinmux = < 0x127 >; /* in modules\hal\stm32\dts\st\u5\stm32u5a5zjtxq-pinctrl.dtsi:3414 */
				bias-pull-up;       /* in modules\hal\stm32\dts\st\u5\stm32u5a5zjtxq-pinctrl.dtsi:3415 */
				phandle = < 0x5 >;  /* in zephyr\boards\st\nucleo_u5a5zj_q\nucleo_u5a5zj_q.dts:70 */
			};

			/* node '/soc/pin-controller@42020000/lpuart1_tx_pg7' defined in modules\hal\stm32\dts\st\u5\stm32u5a5zjtxq-pinctrl.dtsi:3433 */
			lpuart1_tx_pg7: lpuart1_tx_pg7 {
				pinmux = < 0xce8 >; /* in modules\hal\stm32\dts\st\u5\stm32u5a5zjtxq-pinctrl.dtsi:3434 */
				bias-pull-up;       /* in modules\hal\stm32\dts\st\u5\stm32u5a5zjtxq-pinctrl.dtsi:3435 */
				phandle = < 0x7 >;  /* in zephyr\boards\st\nucleo_u5a5zj_q\nucleo_u5a5zj_q-common.dtsi:93 */
			};

			/* node '/soc/pin-controller@42020000/usart2_tx_pd5' defined in modules\hal\stm32\dts\st\u5\stm32u5a5zjtxq-pinctrl.dtsi:3448 */
			usart2_tx_pd5: usart2_tx_pd5 {
				pinmux = < 0x6a7 >; /* in modules\hal\stm32\dts\st\u5\stm32u5a5zjtxq-pinctrl.dtsi:3449 */
				bias-pull-up;       /* in modules\hal\stm32\dts\st\u5\stm32u5a5zjtxq-pinctrl.dtsi:3450 */
				phandle = < 0x24 >; /* in zephyr\boards\st\nucleo_u5a5zj_q\nucleo_u5a5zj_q-common.dtsi:100 */
			};

			/* node '/soc/pin-controller@42020000/usb_otg_hs_dm_pa11' defined in modules\hal\stm32\dts\st\u5\stm32u5a5zjtxq-pinctrl.dtsi:3537 */
			usb_otg_hs_dm_pa11: usb_otg_hs_dm_pa11 {
				pinmux = < 0x170 >; /* in modules\hal\stm32\dts\st\u5\stm32u5a5zjtxq-pinctrl.dtsi:3538 */
				phandle = < 0x27 >; /* in zephyr\boards\st\nucleo_u5a5zj_q\nucleo_u5a5zj_q.dts:81 */
			};

			/* node '/soc/pin-controller@42020000/usb_otg_hs_dp_pa12' defined in modules\hal\stm32\dts\st\u5\stm32u5a5zjtxq-pinctrl.dtsi:3541 */
			usb_otg_hs_dp_pa12: usb_otg_hs_dp_pa12 {
				pinmux = < 0x190 >; /* in modules\hal\stm32\dts\st\u5\stm32u5a5zjtxq-pinctrl.dtsi:3542 */
				phandle = < 0x28 >; /* in zephyr\boards\st\nucleo_u5a5zj_q\nucleo_u5a5zj_q.dts:81 */
			};
		};

		/* node '/soc/watchdog@40003000' defined in zephyr\dts\arm\st\u5\stm32u5.dtsi:279 */
		iwdg: watchdog@40003000 {
			compatible = "st,stm32-watchdog"; /* in zephyr\dts\arm\st\u5\stm32u5.dtsi:280 */
			reg = < 0x40003000 0x400 >;       /* in zephyr\dts\arm\st\u5\stm32u5.dtsi:281 */
			interrupts = < 0x1b 0x0 >;        /* in zephyr\dts\arm\st\u5\stm32u5.dtsi:282 */
			status = "okay";                  /* in zephyr\boards\st\nucleo_u5a5zj_q\nucleo_u5a5zj_q-common.dtsi:172 */
		};

		/* node '/soc/watchdog@40002c00' defined in zephyr\dts\arm\st\u5\stm32u5.dtsi:286 */
		wwdg: wwdg1: watchdog@40002c00 {
			compatible = "st,stm32-window-watchdog"; /* in zephyr\dts\arm\st\u5\stm32u5.dtsi:287 */
			reg = < 0x40002c00 0x1000 >;             /* in zephyr\dts\arm\st\u5\stm32u5.dtsi:288 */
			clocks = < &rcc 0x9c 0x800 >;            /* in zephyr\dts\arm\st\u5\stm32u5.dtsi:289 */
			interrupts = < 0x0 0x7 >;                /* in zephyr\dts\arm\st\u5\stm32u5.dtsi:290 */
			status = "disabled";                     /* in zephyr\dts\arm\st\u5\stm32u5.dtsi:291 */
		};

		/* node '/soc/memory@40036400' defined in zephyr\dts\arm\st\u5\stm32u5.dtsi:294 */
		backup_sram: memory@40036400 {
			compatible = "zephyr,memory-region",
			             "st,stm32-backup-sram";  /* in zephyr\dts\arm\st\u5\stm32u5.dtsi:295 */
			reg = < 0x40036400 0x800 >;           /* in zephyr\dts\arm\st\u5\stm32u5.dtsi:296 */
			clocks = < &rcc 0x88 0x10020000 >;    /* in zephyr\dts\arm\st\u5\stm32u5.dtsi:298 */
			zephyr,memory-region = "BACKUP_SRAM"; /* in zephyr\dts\arm\st\u5\stm32u5.dtsi:299 */
			status = "disabled";                  /* in zephyr\dts\arm\st\u5\stm32u5.dtsi:300 */
		};

		/* node '/soc/serial@40013800' defined in zephyr\dts\arm\st\u5\stm32u5.dtsi:303 */
		usart1: serial@40013800 {
			compatible = "st,stm32-usart",
			             "st,stm32-uart";                   /* in zephyr\dts\arm\st\u5\stm32u5.dtsi:304 */
			reg = < 0x40013800 0x400 >;                     /* in zephyr\dts\arm\st\u5\stm32u5.dtsi:305 */
			clocks = < &rcc 0xa4 0x4000 >;                  /* in zephyr\dts\arm\st\u5\stm32u5.dtsi:306 */
			resets = < &rctl 0xf8e >;                       /* in zephyr\dts\arm\st\u5\stm32u5.dtsi:307 */
			interrupts = < 0x3d 0x0 >;                      /* in zephyr\dts\arm\st\u5\stm32u5.dtsi:308 */
			pinctrl-0 = < &usart1_tx_pa9 &usart1_rx_pa10 >; /* in zephyr\boards\st\nucleo_u5a5zj_q\nucleo_u5a5zj_q.dts:70 */
			pinctrl-names = "default";                      /* in zephyr\boards\st\nucleo_u5a5zj_q\nucleo_u5a5zj_q.dts:71 */
			current-speed = < 0x1c200 >;                    /* in zephyr\boards\st\nucleo_u5a5zj_q\nucleo_u5a5zj_q.dts:72 */
			status = "okay";                                /* in zephyr\boards\st\nucleo_u5a5zj_q\nucleo_u5a5zj_q.dts:73 */
		};

		/* node '/soc/serial@40004800' defined in zephyr\dts\arm\st\u5\stm32u5.dtsi:312 */
		usart3: serial@40004800 {
			compatible = "st,stm32-usart",
			             "st,stm32-uart";   /* in zephyr\dts\arm\st\u5\stm32u5.dtsi:313 */
			reg = < 0x40004800 0x400 >;     /* in zephyr\dts\arm\st\u5\stm32u5.dtsi:314 */
			clocks = < &rcc 0x9c 0x40000 >; /* in zephyr\dts\arm\st\u5\stm32u5.dtsi:315 */
			resets = < &rctl 0xe92 >;       /* in zephyr\dts\arm\st\u5\stm32u5.dtsi:316 */
			interrupts = < 0x3f 0x0 >;      /* in zephyr\dts\arm\st\u5\stm32u5.dtsi:317 */
			status = "disabled";            /* in zephyr\dts\arm\st\u5\stm32u5.dtsi:318 */
		};

		/* node '/soc/serial@40004c00' defined in zephyr\dts\arm\st\u5\stm32u5.dtsi:321 */
		uart4: serial@40004c00 {
			compatible = "st,stm32-uart";   /* in zephyr\dts\arm\st\u5\stm32u5.dtsi:322 */
			reg = < 0x40004c00 0x400 >;     /* in zephyr\dts\arm\st\u5\stm32u5.dtsi:323 */
			clocks = < &rcc 0x9c 0x80000 >; /* in zephyr\dts\arm\st\u5\stm32u5.dtsi:324 */
			resets = < &rctl 0xe93 >;       /* in zephyr\dts\arm\st\u5\stm32u5.dtsi:325 */
			interrupts = < 0x40 0x0 >;      /* in zephyr\dts\arm\st\u5\stm32u5.dtsi:326 */
			status = "disabled";            /* in zephyr\dts\arm\st\u5\stm32u5.dtsi:327 */
		};

		/* node '/soc/serial@40005000' defined in zephyr\dts\arm\st\u5\stm32u5.dtsi:330 */
		uart5: serial@40005000 {
			compatible = "st,stm32-uart";    /* in zephyr\dts\arm\st\u5\stm32u5.dtsi:331 */
			reg = < 0x40005000 0x400 >;      /* in zephyr\dts\arm\st\u5\stm32u5.dtsi:332 */
			clocks = < &rcc 0x9c 0x100000 >; /* in zephyr\dts\arm\st\u5\stm32u5.dtsi:333 */
			resets = < &rctl 0xe94 >;        /* in zephyr\dts\arm\st\u5\stm32u5.dtsi:334 */
			interrupts = < 0x41 0x0 >;       /* in zephyr\dts\arm\st\u5\stm32u5.dtsi:335 */
			status = "disabled";             /* in zephyr\dts\arm\st\u5\stm32u5.dtsi:336 */
		};

		/* node '/soc/serial@46002400' defined in zephyr\dts\arm\st\u5\stm32u5.dtsi:339 */
		lpuart1: arduino_serial: serial@46002400 {
			compatible = "st,stm32-lpuart",
			             "st,stm32-uart";                    /* in zephyr\dts\arm\st\u5\stm32u5.dtsi:340 */
			reg = < 0x46002400 0x400 >;                      /* in zephyr\dts\arm\st\u5\stm32u5.dtsi:341 */
			clocks = < &rcc 0xa8 0x40 >;                     /* in zephyr\dts\arm\st\u5\stm32u5.dtsi:342 */
			resets = < &rctl 0x1006 >;                       /* in zephyr\dts\arm\st\u5\stm32u5.dtsi:343 */
			interrupts = < 0x42 0x0 >;                       /* in zephyr\dts\arm\st\u5\stm32u5.dtsi:344 */
			pinctrl-0 = < &lpuart1_tx_pg7 &lpuart1_rx_pg8 >; /* in zephyr\boards\st\nucleo_u5a5zj_q\nucleo_u5a5zj_q-common.dtsi:93 */
			pinctrl-names = "default";                       /* in zephyr\boards\st\nucleo_u5a5zj_q\nucleo_u5a5zj_q-common.dtsi:94 */
			current-speed = < 0x1c200 >;                     /* in zephyr\boards\st\nucleo_u5a5zj_q\nucleo_u5a5zj_q-common.dtsi:95 */
			status = "okay";                                 /* in zephyr\boards\st\nucleo_u5a5zj_q\nucleo_u5a5zj_q-common.dtsi:96 */
		};

		/* node '/soc/spi@40013000' defined in zephyr\dts\arm\st\u5\stm32u5.dtsi:348 */
		spi1: arduino_spi: spi@40013000 {
			compatible = "st,stm32h7-spi",
			             "st,stm32-spi-fifo",
			             "st,stm32-spi";                                 /* in zephyr\dts\arm\st\u5\stm32u5.dtsi:349 */
			#address-cells = < 0x1 >;                                    /* in zephyr\dts\arm\st\u5\stm32u5.dtsi:350 */
			#size-cells = < 0x0 >;                                       /* in zephyr\dts\arm\st\u5\stm32u5.dtsi:351 */
			reg = < 0x40013000 0x400 >;                                  /* in zephyr\dts\arm\st\u5\stm32u5.dtsi:352 */
			interrupts = < 0x3b 0x5 >;                                   /* in zephyr\dts\arm\st\u5\stm32u5.dtsi:353 */
			clocks = < &rcc 0xa4 0x1000 >;                               /* in zephyr\dts\arm\st\u5\stm32u5.dtsi:354 */
			st,spi-data-width = "full-4-to-32-bit";                      /* in zephyr\dts\arm\st\u5\stm32u5.dtsi:355 */
			pinctrl-0 = < &spi1_sck_pa5 &spi1_miso_pa6 &spi1_mosi_pa7 >; /* in zephyr\boards\st\nucleo_u5a5zj_q\nucleo_u5a5zj_q-common.dtsi:121 */
			pinctrl-names = "default";                                   /* in zephyr\boards\st\nucleo_u5a5zj_q\nucleo_u5a5zj_q-common.dtsi:122 */
			cs-gpios = < &gpiod 0xe 0x1 >;                               /* in zephyr\boards\st\nucleo_u5a5zj_q\nucleo_u5a5zj_q-common.dtsi:123 */
			status = "okay";                                             /* in zephyr\boards\st\nucleo_u5a5zj_q\nucleo_u5a5zj_q-common.dtsi:124 */
		};

		/* node '/soc/spi@40003800' defined in zephyr\dts\arm\st\u5\stm32u5.dtsi:359 */
		spi2: spi@40003800 {
			compatible = "st,stm32h7-spi",
			             "st,stm32-spi-fifo",
			             "st,stm32-spi";            /* in zephyr\dts\arm\st\u5\stm32u5.dtsi:360 */
			#address-cells = < 0x1 >;               /* in zephyr\dts\arm\st\u5\stm32u5.dtsi:361 */
			#size-cells = < 0x0 >;                  /* in zephyr\dts\arm\st\u5\stm32u5.dtsi:362 */
			reg = < 0x40003800 0x400 >;             /* in zephyr\dts\arm\st\u5\stm32u5.dtsi:363 */
			interrupts = < 0x3c 0x5 >;              /* in zephyr\dts\arm\st\u5\stm32u5.dtsi:364 */
			clocks = < &rcc 0x9c 0x4000 >;          /* in zephyr\dts\arm\st\u5\stm32u5.dtsi:365 */
			st,spi-data-width = "full-4-to-32-bit"; /* in zephyr\dts\arm\st\u5\stm32u5.dtsi:366 */
			status = "disabled";                    /* in zephyr\dts\arm\st\u5\stm32u5.dtsi:367 */
		};

		/* node '/soc/spi@46002000' defined in zephyr\dts\arm\st\u5\stm32u5.dtsi:370 */
		spi3: spi@46002000 {
			compatible = "st,stm32h7-spi",
			             "st,stm32-spi-fifo",
			             "st,stm32-spi";            /* in zephyr\dts\arm\st\u5\stm32u5.dtsi:371 */
			#address-cells = < 0x1 >;               /* in zephyr\dts\arm\st\u5\stm32u5.dtsi:372 */
			#size-cells = < 0x0 >;                  /* in zephyr\dts\arm\st\u5\stm32u5.dtsi:373 */
			reg = < 0x46002000 0x400 >;             /* in zephyr\dts\arm\st\u5\stm32u5.dtsi:374 */
			interrupts = < 0x63 0x5 >;              /* in zephyr\dts\arm\st\u5\stm32u5.dtsi:375 */
			clocks = < &rcc 0xa8 0x20 >;            /* in zephyr\dts\arm\st\u5\stm32u5.dtsi:376 */
			st,spi-data-width = "limited-8-16-bit"; /* in zephyr\dts\arm\st\u5\stm32u5.dtsi:377 */
			status = "disabled";                    /* in zephyr\dts\arm\st\u5\stm32u5.dtsi:378 */
		};

		/* node '/soc/i2c@40005400' defined in zephyr\dts\arm\st\u5\stm32u5.dtsi:381 */
		i2c1: arduino_i2c: i2c@40005400 {
			compatible = "st,stm32-i2c-v2";              /* in zephyr\dts\arm\st\u5\stm32u5.dtsi:382 */
			#address-cells = < 0x1 >;                    /* in zephyr\dts\arm\st\u5\stm32u5.dtsi:384 */
			#size-cells = < 0x0 >;                       /* in zephyr\dts\arm\st\u5\stm32u5.dtsi:385 */
			reg = < 0x40005400 0x400 >;                  /* in zephyr\dts\arm\st\u5\stm32u5.dtsi:386 */
			clocks = < &rcc 0x9c 0x200000 >;             /* in zephyr\dts\arm\st\u5\stm32u5.dtsi:387 */
			interrupts = < 0x37 0x0 >,
			             < 0x38 0x0 >;                   /* in zephyr\dts\arm\st\u5\stm32u5.dtsi:388 */
			interrupt-names = "event",
			                  "error";                   /* in zephyr\dts\arm\st\u5\stm32u5.dtsi:389 */
			pinctrl-0 = < &i2c1_scl_pb8 &i2c1_sda_pb9 >; /* in zephyr\boards\st\nucleo_u5a5zj_q\nucleo_u5a5zj_q-common.dtsi:107 */
			pinctrl-names = "default";                   /* in zephyr\boards\st\nucleo_u5a5zj_q\nucleo_u5a5zj_q-common.dtsi:108 */
			status = "okay";                             /* in zephyr\boards\st\nucleo_u5a5zj_q\nucleo_u5a5zj_q-common.dtsi:109 */
			clock-frequency = < 0x61a80 >;               /* in zephyr\boards\st\nucleo_u5a5zj_q\nucleo_u5a5zj_q-common.dtsi:110 */
			phandle = < 0x39 >;                          /* in zephyr\dts\arm\st\u5\stm32u5.dtsi:1072 */
		};

		/* node '/soc/i2c@40005800' defined in zephyr\dts\arm\st\u5\stm32u5.dtsi:393 */
		i2c2: i2c@40005800 {
			compatible = "st,stm32-i2c-v2";              /* in zephyr\dts\arm\st\u5\stm32u5.dtsi:394 */
			#address-cells = < 0x1 >;                    /* in zephyr\dts\arm\st\u5\stm32u5.dtsi:396 */
			#size-cells = < 0x0 >;                       /* in zephyr\dts\arm\st\u5\stm32u5.dtsi:397 */
			reg = < 0x40005800 0x400 >;                  /* in zephyr\dts\arm\st\u5\stm32u5.dtsi:398 */
			clocks = < &rcc 0x9c 0x400000 >;             /* in zephyr\dts\arm\st\u5\stm32u5.dtsi:399 */
			interrupts = < 0x39 0x0 >,
			             < 0x3a 0x0 >;                   /* in zephyr\dts\arm\st\u5\stm32u5.dtsi:400 */
			interrupt-names = "event",
			                  "error";                   /* in zephyr\dts\arm\st\u5\stm32u5.dtsi:401 */
			pinctrl-0 = < &i2c2_scl_pf1 &i2c2_sda_pf0 >; /* in zephyr\boards\st\nucleo_u5a5zj_q\nucleo_u5a5zj_q-common.dtsi:114 */
			pinctrl-names = "default";                   /* in zephyr\boards\st\nucleo_u5a5zj_q\nucleo_u5a5zj_q-common.dtsi:115 */
			status = "okay";                             /* in zephyr\boards\st\nucleo_u5a5zj_q\nucleo_u5a5zj_q-common.dtsi:116 */
			clock-frequency = < 0x61a80 >;               /* in zephyr\boards\st\nucleo_u5a5zj_q\nucleo_u5a5zj_q-common.dtsi:117 */
			phandle = < 0x3a >;                          /* in zephyr\dts\arm\st\u5\stm32u5.dtsi:1080 */
		};

		/* node '/soc/i2c@46002800' defined in zephyr\dts\arm\st\u5\stm32u5.dtsi:405 */
		i2c3: i2c@46002800 {
			compatible = "st,stm32-i2c-v2"; /* in zephyr\dts\arm\st\u5\stm32u5.dtsi:406 */
			clock-frequency = < 0x186a0 >;  /* in zephyr\dts\arm\st\u5\stm32u5.dtsi:407 */
			#address-cells = < 0x1 >;       /* in zephyr\dts\arm\st\u5\stm32u5.dtsi:408 */
			#size-cells = < 0x0 >;          /* in zephyr\dts\arm\st\u5\stm32u5.dtsi:409 */
			reg = < 0x46002800 0x400 >;     /* in zephyr\dts\arm\st\u5\stm32u5.dtsi:410 */
			clocks = < &rcc 0xa8 0x80 >;    /* in zephyr\dts\arm\st\u5\stm32u5.dtsi:411 */
			interrupts = < 0x58 0x0 >,
			             < 0x59 0x0 >;      /* in zephyr\dts\arm\st\u5\stm32u5.dtsi:412 */
			interrupt-names = "event",
			                  "error";      /* in zephyr\dts\arm\st\u5\stm32u5.dtsi:413 */
			status = "disabled";            /* in zephyr\dts\arm\st\u5\stm32u5.dtsi:414 */
			phandle = < 0x3b >;             /* in zephyr\dts\arm\st\u5\stm32u5.dtsi:1088 */
		};

		/* node '/soc/i2c@40008400' defined in zephyr\dts\arm\st\u5\stm32u5.dtsi:417 */
		i2c4: i2c@40008400 {
			compatible = "st,stm32-i2c-v2"; /* in zephyr\dts\arm\st\u5\stm32u5.dtsi:418 */
			clock-frequency = < 0x186a0 >;  /* in zephyr\dts\arm\st\u5\stm32u5.dtsi:419 */
			#address-cells = < 0x1 >;       /* in zephyr\dts\arm\st\u5\stm32u5.dtsi:420 */
			#size-cells = < 0x0 >;          /* in zephyr\dts\arm\st\u5\stm32u5.dtsi:421 */
			reg = < 0x40008400 0x400 >;     /* in zephyr\dts\arm\st\u5\stm32u5.dtsi:422 */
			clocks = < &rcc 0xa0 0x2 >;     /* in zephyr\dts\arm\st\u5\stm32u5.dtsi:423 */
			interrupts = < 0x65 0x0 >,
			             < 0x64 0x0 >;      /* in zephyr\dts\arm\st\u5\stm32u5.dtsi:424 */
			interrupt-names = "event",
			                  "error";      /* in zephyr\dts\arm\st\u5\stm32u5.dtsi:425 */
			status = "disabled";            /* in zephyr\dts\arm\st\u5\stm32u5.dtsi:426 */
			phandle = < 0x3c >;             /* in zephyr\dts\arm\st\u5\stm32u5.dtsi:1096 */
		};

		/* node '/soc/timers@46004400' defined in zephyr\dts\arm\st\u5\stm32u5.dtsi:429 */
		lptim1: timers@46004400 {
			compatible = "st,stm32-lptim"; /* in zephyr\dts\arm\st\u5\stm32u5.dtsi:430 */
			#address-cells = < 0x1 >;      /* in zephyr\dts\arm\st\u5\stm32u5.dtsi:431 */
			#size-cells = < 0x0 >;         /* in zephyr\dts\arm\st\u5\stm32u5.dtsi:432 */
			reg = < 0x46004400 0x400 >;    /* in zephyr\dts\arm\st\u5\stm32u5.dtsi:433 */
			clocks = < &rcc 0xa8 0x800 >;  /* in zephyr\dts\arm\st\u5\stm32u5.dtsi:434 */
			resets = < &rctl 0x100b >;     /* in zephyr\dts\arm\st\u5\stm32u5.dtsi:435 */
			interrupts = < 0x43 0x1 >;     /* in zephyr\dts\arm\st\u5\stm32u5.dtsi:436 */
			interrupt-names = "wakeup";    /* in zephyr\dts\arm\st\u5\stm32u5.dtsi:437 */
			status = "disabled";           /* in zephyr\dts\arm\st\u5\stm32u5.dtsi:438 */
		};

		/* node '/soc/timers@40009400' defined in zephyr\dts\arm\st\u5\stm32u5.dtsi:441 */
		lptim2: timers@40009400 {
			compatible = "st,stm32-lptim"; /* in zephyr\dts\arm\st\u5\stm32u5.dtsi:442 */
			#address-cells = < 0x1 >;      /* in zephyr\dts\arm\st\u5\stm32u5.dtsi:443 */
			#size-cells = < 0x0 >;         /* in zephyr\dts\arm\st\u5\stm32u5.dtsi:444 */
			reg = < 0x40009400 0x400 >;    /* in zephyr\dts\arm\st\u5\stm32u5.dtsi:445 */
			clocks = < &rcc 0xa0 0x20 >;   /* in zephyr\dts\arm\st\u5\stm32u5.dtsi:446 */
			resets = < &rctl 0xf05 >;      /* in zephyr\dts\arm\st\u5\stm32u5.dtsi:447 */
			interrupts = < 0x44 0x0 >;     /* in zephyr\dts\arm\st\u5\stm32u5.dtsi:448 */
			interrupt-names = "global";    /* in zephyr\dts\arm\st\u5\stm32u5.dtsi:449 */
			status = "disabled";           /* in zephyr\dts\arm\st\u5\stm32u5.dtsi:450 */
		};

		/* node '/soc/timers@46004800' defined in zephyr\dts\arm\st\u5\stm32u5.dtsi:453 */
		lptim3: timers@46004800 {
			compatible = "st,stm32-lptim"; /* in zephyr\dts\arm\st\u5\stm32u5.dtsi:454 */
			#address-cells = < 0x1 >;      /* in zephyr\dts\arm\st\u5\stm32u5.dtsi:455 */
			#size-cells = < 0x0 >;         /* in zephyr\dts\arm\st\u5\stm32u5.dtsi:456 */
			reg = < 0x46004800 0x400 >;    /* in zephyr\dts\arm\st\u5\stm32u5.dtsi:457 */
			clocks = < &rcc 0xa8 0x1000 >; /* in zephyr\dts\arm\st\u5\stm32u5.dtsi:458 */
			resets = < &rctl 0x100c >;     /* in zephyr\dts\arm\st\u5\stm32u5.dtsi:459 */
			interrupts = < 0x62 0x0 >;     /* in zephyr\dts\arm\st\u5\stm32u5.dtsi:460 */
			interrupt-names = "global";    /* in zephyr\dts\arm\st\u5\stm32u5.dtsi:461 */
			status = "disabled";           /* in zephyr\dts\arm\st\u5\stm32u5.dtsi:462 */
		};

		/* node '/soc/timers@46004c00' defined in zephyr\dts\arm\st\u5\stm32u5.dtsi:465 */
		lptim4: timers@46004c00 {
			compatible = "st,stm32-lptim"; /* in zephyr\dts\arm\st\u5\stm32u5.dtsi:466 */
			#address-cells = < 0x1 >;      /* in zephyr\dts\arm\st\u5\stm32u5.dtsi:467 */
			#size-cells = < 0x0 >;         /* in zephyr\dts\arm\st\u5\stm32u5.dtsi:468 */
			reg = < 0x46004c00 0x400 >;    /* in zephyr\dts\arm\st\u5\stm32u5.dtsi:469 */
			clocks = < &rcc 0xa8 0x2000 >; /* in zephyr\dts\arm\st\u5\stm32u5.dtsi:470 */
			resets = < &rctl 0x100d >;     /* in zephyr\dts\arm\st\u5\stm32u5.dtsi:471 */
			interrupts = < 0x6e 0x0 >;     /* in zephyr\dts\arm\st\u5\stm32u5.dtsi:472 */
			interrupt-names = "global";    /* in zephyr\dts\arm\st\u5\stm32u5.dtsi:473 */
			status = "disabled";           /* in zephyr\dts\arm\st\u5\stm32u5.dtsi:474 */
		};

		/* node '/soc/rtc@46007800' defined in zephyr\dts\arm\st\u5\stm32u5.dtsi:477 */
		rtc: rtc@46007800 {
			compatible = "st,stm32-rtc";     /* in zephyr\dts\arm\st\u5\stm32u5.dtsi:478 */
			reg = < 0x46007800 0x400 >;      /* in zephyr\dts\arm\st\u5\stm32u5.dtsi:479 */
			interrupts = < 0x2 0x0 >;        /* in zephyr\dts\arm\st\u5\stm32u5.dtsi:480 */
			prescaler = < 0x8000 >;          /* in zephyr\dts\arm\st\u5\stm32u5.dtsi:482 */
			alarms-count = < 0x2 >;          /* in zephyr\dts\arm\st\u5\stm32u5.dtsi:483 */
			clocks = < &rcc 0xa8 0x200000 >,
			         < &rcc 0x2 0x12800f0 >; /* in zephyr\boards\st\nucleo_u5a5zj_q\nucleo_u5a5zj_q-common.dtsi:188 */
			status = "okay";                 /* in zephyr\boards\st\nucleo_u5a5zj_q\nucleo_u5a5zj_q-common.dtsi:190 */
		};

		/* node '/soc/sai1@40015404' defined in zephyr\dts\arm\st\u5\stm32u5.dtsi:487 */
		sai1_a: sai1@40015404 {
			compatible = "st,stm32-sai";         /* in zephyr\dts\arm\st\u5\stm32u5.dtsi:488 */
			#address-cells = < 0x1 >;            /* in zephyr\dts\arm\st\u5\stm32u5.dtsi:489 */
			#size-cells = < 0x0 >;               /* in zephyr\dts\arm\st\u5\stm32u5.dtsi:490 */
			reg = < 0x40015404 0x20 >;           /* in zephyr\dts\arm\st\u5\stm32u5.dtsi:491 */
			clocks = < &rcc 0xa4 0x200000 >,
			         < &rcc 0x12 0x4500e4 >;     /* in zephyr\dts\arm\st\u5\stm32u5.dtsi:492 */
			dmas = < &gpdma1 0x1 0x24 0x22800 >; /* in zephyr\dts\arm\st\u5\stm32u5.dtsi:494 */
			status = "disabled";                 /* in zephyr\dts\arm\st\u5\stm32u5.dtsi:496 */
		};

		/* node '/soc/sai1@40015424' defined in zephyr\dts\arm\st\u5\stm32u5.dtsi:499 */
		sai1_b: sai1@40015424 {
			compatible = "st,stm32-sai";         /* in zephyr\dts\arm\st\u5\stm32u5.dtsi:500 */
			#address-cells = < 0x1 >;            /* in zephyr\dts\arm\st\u5\stm32u5.dtsi:501 */
			#size-cells = < 0x0 >;               /* in zephyr\dts\arm\st\u5\stm32u5.dtsi:502 */
			reg = < 0x40015424 0x20 >;           /* in zephyr\dts\arm\st\u5\stm32u5.dtsi:503 */
			clocks = < &rcc 0xa4 0x200000 >,
			         < &rcc 0x12 0x4500e4 >;     /* in zephyr\dts\arm\st\u5\stm32u5.dtsi:504 */
			dmas = < &gpdma1 0x0 0x25 0x22800 >; /* in zephyr\dts\arm\st\u5\stm32u5.dtsi:506 */
			status = "disabled";                 /* in zephyr\dts\arm\st\u5\stm32u5.dtsi:508 */
		};

		/* node '/soc/timers@40012c00' defined in zephyr\dts\arm\st\u5\stm32u5.dtsi:511 */
		timers1: timers@40012c00 {
			compatible = "st,stm32-timers"; /* in zephyr\dts\arm\st\u5\stm32u5.dtsi:512 */
			reg = < 0x40012c00 0x400 >;     /* in zephyr\dts\arm\st\u5\stm32u5.dtsi:513 */
			clocks = < &rcc 0xa4 0x800 >,
			         < &rcc 0xe 0xff >;     /* in zephyr\dts\arm\st\u5\stm32u5.dtsi:514 */
			resets = < &rctl 0xf8b >;       /* in zephyr\dts\arm\st\u5\stm32u5.dtsi:516 */
			interrupts = < 0x29 0x0 >,
			             < 0x2a 0x0 >,
			             < 0x2b 0x0 >,
			             < 0x2c 0x0 >;      /* in zephyr\dts\arm\st\u5\stm32u5.dtsi:517 */
			interrupt-names = "brk",
			                  "up",
			                  "trgcom",
			                  "cc";         /* in zephyr\dts\arm\st\u5\stm32u5.dtsi:518 */
			status = "disabled";            /* in zephyr\dts\arm\st\u5\stm32u5.dtsi:519 */

			/* node '/soc/timers@40012c00/pwm' defined in zephyr\dts\arm\st\u5\stm32u5.dtsi:521 */
			pwm {
				compatible = "st,stm32-pwm"; /* in zephyr\dts\arm\st\u5\stm32u5.dtsi:522 */
				status = "disabled";         /* in zephyr\dts\arm\st\u5\stm32u5.dtsi:523 */
				#pwm-cells = < 0x3 >;        /* in zephyr\dts\arm\st\u5\stm32u5.dtsi:524 */
			};

			/* node '/soc/timers@40012c00/counter' defined in zephyr\dts\arm\st\u5\stm32u5.dtsi:527 */
			counter {
				compatible = "st,stm32-counter"; /* in zephyr\dts\arm\st\u5\stm32u5.dtsi:528 */
				status = "disabled";             /* in zephyr\dts\arm\st\u5\stm32u5.dtsi:529 */
			};

			/* node '/soc/timers@40012c00/qdec' defined in zephyr\dts\arm\st\u5\stm32u5.dtsi:532 */
			qdec {
				compatible = "st,stm32-qdec";    /* in zephyr\dts\arm\st\u5\stm32u5.dtsi:533 */
				st,input-filter-level = < 0x0 >; /* in zephyr\dts\arm\st\u5\stm32u5.dtsi:534 */
				status = "disabled";             /* in zephyr\dts\arm\st\u5\stm32u5.dtsi:535 */
			};
		};

		/* node '/soc/timers@40000000' defined in zephyr\dts\arm\st\u5\stm32u5.dtsi:539 */
		timers2: timers@40000000 {
			compatible = "st,stm32-timers"; /* in zephyr\dts\arm\st\u5\stm32u5.dtsi:540 */
			reg = < 0x40000000 0x400 >;     /* in zephyr\dts\arm\st\u5\stm32u5.dtsi:541 */
			clocks = < &rcc 0x9c 0x1 >,
			         < &rcc 0xd 0xff >;     /* in zephyr\dts\arm\st\u5\stm32u5.dtsi:542 */
			resets = < &rctl 0xe80 >;       /* in zephyr\dts\arm\st\u5\stm32u5.dtsi:544 */
			interrupts = < 0x2d 0x0 >;      /* in zephyr\dts\arm\st\u5\stm32u5.dtsi:545 */
			interrupt-names = "global";     /* in zephyr\dts\arm\st\u5\stm32u5.dtsi:546 */
			status = "disabled";            /* in zephyr\dts\arm\st\u5\stm32u5.dtsi:547 */

			/* node '/soc/timers@40000000/pwm' defined in zephyr\dts\arm\st\u5\stm32u5.dtsi:549 */
			pwm {
				compatible = "st,stm32-pwm"; /* in zephyr\dts\arm\st\u5\stm32u5.dtsi:550 */
				status = "disabled";         /* in zephyr\dts\arm\st\u5\stm32u5.dtsi:551 */
				#pwm-cells = < 0x3 >;        /* in zephyr\dts\arm\st\u5\stm32u5.dtsi:552 */
			};

			/* node '/soc/timers@40000000/counter' defined in zephyr\dts\arm\st\u5\stm32u5.dtsi:555 */
			counter {
				compatible = "st,stm32-counter"; /* in zephyr\dts\arm\st\u5\stm32u5.dtsi:556 */
				status = "disabled";             /* in zephyr\dts\arm\st\u5\stm32u5.dtsi:557 */
			};

			/* node '/soc/timers@40000000/qdec' defined in zephyr\dts\arm\st\u5\stm32u5.dtsi:560 */
			qdec {
				compatible = "st,stm32-qdec";    /* in zephyr\dts\arm\st\u5\stm32u5.dtsi:561 */
				st,input-filter-level = < 0x0 >; /* in zephyr\dts\arm\st\u5\stm32u5.dtsi:562 */
				status = "disabled";             /* in zephyr\dts\arm\st\u5\stm32u5.dtsi:563 */
			};
		};

		/* node '/soc/timers@40000400' defined in zephyr\dts\arm\st\u5\stm32u5.dtsi:567 */
		timers3: timers@40000400 {
			compatible = "st,stm32-timers"; /* in zephyr\dts\arm\st\u5\stm32u5.dtsi:568 */
			reg = < 0x40000400 0x400 >;     /* in zephyr\dts\arm\st\u5\stm32u5.dtsi:569 */
			clocks = < &rcc 0x9c 0x2 >,
			         < &rcc 0xd 0xff >;     /* in zephyr\dts\arm\st\u5\stm32u5.dtsi:570 */
			resets = < &rctl 0xe81 >;       /* in zephyr\dts\arm\st\u5\stm32u5.dtsi:572 */
			interrupts = < 0x2e 0x0 >;      /* in zephyr\dts\arm\st\u5\stm32u5.dtsi:573 */
			interrupt-names = "global";     /* in zephyr\dts\arm\st\u5\stm32u5.dtsi:574 */
			st,prescaler = < 0x2710 >;      /* in zephyr\boards\st\nucleo_u5a5zj_q\nucleo_u5a5zj_q-common.dtsi:150 */
			status = "okay";                /* in zephyr\boards\st\nucleo_u5a5zj_q\nucleo_u5a5zj_q-common.dtsi:151 */

			/* node '/soc/timers@40000400/pwm' defined in zephyr\dts\arm\st\u5\stm32u5.dtsi:577 */
			pwm3: pwm {
				compatible = "st,stm32-pwm";   /* in zephyr\dts\arm\st\u5\stm32u5.dtsi:578 */
				#pwm-cells = < 0x3 >;          /* in zephyr\dts\arm\st\u5\stm32u5.dtsi:580 */
				pinctrl-0 = < &tim3_ch2_pc7 >; /* in zephyr\boards\st\nucleo_u5a5zj_q\nucleo_u5a5zj_q-common.dtsi:154 */
				pinctrl-names = "default";     /* in zephyr\boards\st\nucleo_u5a5zj_q\nucleo_u5a5zj_q-common.dtsi:155 */
				status = "okay";               /* in zephyr\boards\st\nucleo_u5a5zj_q\nucleo_u5a5zj_q-common.dtsi:156 */
				phandle = < 0x40 >;            /* in zephyr\boards\st\nucleo_u5a5zj_q\nucleo_u5a5zj_q-common.dtsi:48 */
			};

			/* node '/soc/timers@40000400/counter' defined in zephyr\dts\arm\st\u5\stm32u5.dtsi:583 */
			counter {
				compatible = "st,stm32-counter"; /* in zephyr\dts\arm\st\u5\stm32u5.dtsi:584 */
				status = "disabled";             /* in zephyr\dts\arm\st\u5\stm32u5.dtsi:585 */
			};

			/* node '/soc/timers@40000400/qdec' defined in zephyr\dts\arm\st\u5\stm32u5.dtsi:588 */
			qdec {
				compatible = "st,stm32-qdec";    /* in zephyr\dts\arm\st\u5\stm32u5.dtsi:589 */
				st,input-filter-level = < 0x0 >; /* in zephyr\dts\arm\st\u5\stm32u5.dtsi:590 */
				status = "disabled";             /* in zephyr\dts\arm\st\u5\stm32u5.dtsi:591 */
			};
		};

		/* node '/soc/timers@40000800' defined in zephyr\dts\arm\st\u5\stm32u5.dtsi:595 */
		timers4: timers@40000800 {
			compatible = "st,stm32-timers"; /* in zephyr\dts\arm\st\u5\stm32u5.dtsi:596 */
			reg = < 0x40000800 0x400 >;     /* in zephyr\dts\arm\st\u5\stm32u5.dtsi:597 */
			clocks = < &rcc 0x9c 0x4 >,
			         < &rcc 0xd 0xff >;     /* in zephyr\dts\arm\st\u5\stm32u5.dtsi:598 */
			resets = < &rctl 0xe82 >;       /* in zephyr\dts\arm\st\u5\stm32u5.dtsi:600 */
			interrupts = < 0x2f 0x0 >;      /* in zephyr\dts\arm\st\u5\stm32u5.dtsi:601 */
			interrupt-names = "global";     /* in zephyr\dts\arm\st\u5\stm32u5.dtsi:602 */
			st,prescaler = < 0x2710 >;      /* in zephyr\boards\st\nucleo_u5a5zj_q\nucleo_u5a5zj_q-common.dtsi:161 */
			status = "okay";                /* in zephyr\boards\st\nucleo_u5a5zj_q\nucleo_u5a5zj_q-common.dtsi:162 */

			/* node '/soc/timers@40000800/pwm' defined in zephyr\dts\arm\st\u5\stm32u5.dtsi:605 */
			pwm4: pwm {
				compatible = "st,stm32-pwm";   /* in zephyr\dts\arm\st\u5\stm32u5.dtsi:606 */
				#pwm-cells = < 0x3 >;          /* in zephyr\dts\arm\st\u5\stm32u5.dtsi:608 */
				pinctrl-0 = < &tim4_ch2_pb7 >; /* in zephyr\boards\st\nucleo_u5a5zj_q\nucleo_u5a5zj_q-common.dtsi:165 */
				pinctrl-names = "default";     /* in zephyr\boards\st\nucleo_u5a5zj_q\nucleo_u5a5zj_q-common.dtsi:166 */
				status = "okay";               /* in zephyr\boards\st\nucleo_u5a5zj_q\nucleo_u5a5zj_q-common.dtsi:167 */
				phandle = < 0x41 >;            /* in zephyr\boards\st\nucleo_u5a5zj_q\nucleo_u5a5zj_q-common.dtsi:53 */
			};

			/* node '/soc/timers@40000800/counter' defined in zephyr\dts\arm\st\u5\stm32u5.dtsi:611 */
			counter {
				compatible = "st,stm32-counter"; /* in zephyr\dts\arm\st\u5\stm32u5.dtsi:612 */
				status = "disabled";             /* in zephyr\dts\arm\st\u5\stm32u5.dtsi:613 */
			};

			/* node '/soc/timers@40000800/qdec' defined in zephyr\dts\arm\st\u5\stm32u5.dtsi:616 */
			qdec {
				compatible = "st,stm32-qdec";    /* in zephyr\dts\arm\st\u5\stm32u5.dtsi:617 */
				st,input-filter-level = < 0x0 >; /* in zephyr\dts\arm\st\u5\stm32u5.dtsi:618 */
				status = "disabled";             /* in zephyr\dts\arm\st\u5\stm32u5.dtsi:619 */
			};
		};

		/* node '/soc/timers@40000c00' defined in zephyr\dts\arm\st\u5\stm32u5.dtsi:623 */
		timers5: timers@40000c00 {
			compatible = "st,stm32-timers"; /* in zephyr\dts\arm\st\u5\stm32u5.dtsi:624 */
			reg = < 0x40000c00 0x400 >;     /* in zephyr\dts\arm\st\u5\stm32u5.dtsi:625 */
			clocks = < &rcc 0x9c 0x8 >,
			         < &rcc 0xd 0xff >;     /* in zephyr\dts\arm\st\u5\stm32u5.dtsi:626 */
			resets = < &rctl 0xe83 >;       /* in zephyr\dts\arm\st\u5\stm32u5.dtsi:628 */
			interrupts = < 0x30 0x0 >;      /* in zephyr\dts\arm\st\u5\stm32u5.dtsi:629 */
			interrupt-names = "global";     /* in zephyr\dts\arm\st\u5\stm32u5.dtsi:630 */
			status = "disabled";            /* in zephyr\dts\arm\st\u5\stm32u5.dtsi:631 */

			/* node '/soc/timers@40000c00/pwm' defined in zephyr\dts\arm\st\u5\stm32u5.dtsi:633 */
			pwm {
				compatible = "st,stm32-pwm"; /* in zephyr\dts\arm\st\u5\stm32u5.dtsi:634 */
				status = "disabled";         /* in zephyr\dts\arm\st\u5\stm32u5.dtsi:635 */
				#pwm-cells = < 0x3 >;        /* in zephyr\dts\arm\st\u5\stm32u5.dtsi:636 */
			};

			/* node '/soc/timers@40000c00/counter' defined in zephyr\dts\arm\st\u5\stm32u5.dtsi:639 */
			counter {
				compatible = "st,stm32-counter"; /* in zephyr\dts\arm\st\u5\stm32u5.dtsi:640 */
				status = "disabled";             /* in zephyr\dts\arm\st\u5\stm32u5.dtsi:641 */
			};

			/* node '/soc/timers@40000c00/qdec' defined in zephyr\dts\arm\st\u5\stm32u5.dtsi:644 */
			qdec {
				compatible = "st,stm32-qdec";    /* in zephyr\dts\arm\st\u5\stm32u5.dtsi:645 */
				st,input-filter-level = < 0x0 >; /* in zephyr\dts\arm\st\u5\stm32u5.dtsi:646 */
				status = "disabled";             /* in zephyr\dts\arm\st\u5\stm32u5.dtsi:647 */
			};
		};

		/* node '/soc/timers@40001000' defined in zephyr\dts\arm\st\u5\stm32u5.dtsi:651 */
		timers6: timers@40001000 {
			compatible = "st,stm32-timers"; /* in zephyr\dts\arm\st\u5\stm32u5.dtsi:652 */
			reg = < 0x40001000 0x400 >;     /* in zephyr\dts\arm\st\u5\stm32u5.dtsi:653 */
			clocks = < &rcc 0x9c 0x10 >,
			         < &rcc 0xd 0xff >;     /* in zephyr\dts\arm\st\u5\stm32u5.dtsi:654 */
			resets = < &rctl 0xe84 >;       /* in zephyr\dts\arm\st\u5\stm32u5.dtsi:656 */
			interrupts = < 0x31 0x0 >;      /* in zephyr\dts\arm\st\u5\stm32u5.dtsi:657 */
			interrupt-names = "global";     /* in zephyr\dts\arm\st\u5\stm32u5.dtsi:658 */
			status = "disabled";            /* in zephyr\dts\arm\st\u5\stm32u5.dtsi:659 */

			/* node '/soc/timers@40001000/pwm' defined in zephyr\dts\arm\st\u5\stm32u5.dtsi:661 */
			pwm {
				compatible = "st,stm32-pwm"; /* in zephyr\dts\arm\st\u5\stm32u5.dtsi:662 */
				status = "disabled";         /* in zephyr\dts\arm\st\u5\stm32u5.dtsi:663 */
				#pwm-cells = < 0x3 >;        /* in zephyr\dts\arm\st\u5\stm32u5.dtsi:664 */
			};

			/* node '/soc/timers@40001000/counter' defined in zephyr\dts\arm\st\u5\stm32u5.dtsi:667 */
			counter {
				compatible = "st,stm32-counter"; /* in zephyr\dts\arm\st\u5\stm32u5.dtsi:668 */
				status = "disabled";             /* in zephyr\dts\arm\st\u5\stm32u5.dtsi:669 */
			};
		};

		/* node '/soc/timers@40001400' defined in zephyr\dts\arm\st\u5\stm32u5.dtsi:673 */
		timers7: timers@40001400 {
			compatible = "st,stm32-timers"; /* in zephyr\dts\arm\st\u5\stm32u5.dtsi:674 */
			reg = < 0x40001400 0x400 >;     /* in zephyr\dts\arm\st\u5\stm32u5.dtsi:675 */
			clocks = < &rcc 0x9c 0x20 >,
			         < &rcc 0xd 0xff >;     /* in zephyr\dts\arm\st\u5\stm32u5.dtsi:676 */
			resets = < &rctl 0xe85 >;       /* in zephyr\dts\arm\st\u5\stm32u5.dtsi:678 */
			interrupts = < 0x32 0x0 >;      /* in zephyr\dts\arm\st\u5\stm32u5.dtsi:679 */
			interrupt-names = "global";     /* in zephyr\dts\arm\st\u5\stm32u5.dtsi:680 */
			status = "disabled";            /* in zephyr\dts\arm\st\u5\stm32u5.dtsi:681 */

			/* node '/soc/timers@40001400/pwm' defined in zephyr\dts\arm\st\u5\stm32u5.dtsi:683 */
			pwm {
				compatible = "st,stm32-pwm"; /* in zephyr\dts\arm\st\u5\stm32u5.dtsi:684 */
				status = "disabled";         /* in zephyr\dts\arm\st\u5\stm32u5.dtsi:685 */
				#pwm-cells = < 0x3 >;        /* in zephyr\dts\arm\st\u5\stm32u5.dtsi:686 */
			};

			/* node '/soc/timers@40001400/counter' defined in zephyr\dts\arm\st\u5\stm32u5.dtsi:689 */
			counter {
				compatible = "st,stm32-counter"; /* in zephyr\dts\arm\st\u5\stm32u5.dtsi:690 */
				status = "disabled";             /* in zephyr\dts\arm\st\u5\stm32u5.dtsi:691 */
			};
		};

		/* node '/soc/timers@40013400' defined in zephyr\dts\arm\st\u5\stm32u5.dtsi:695 */
		timers8: timers@40013400 {
			compatible = "st,stm32-timers"; /* in zephyr\dts\arm\st\u5\stm32u5.dtsi:696 */
			reg = < 0x40013400 0x400 >;     /* in zephyr\dts\arm\st\u5\stm32u5.dtsi:697 */
			clocks = < &rcc 0xa4 0x2000 >,
			         < &rcc 0xe 0xff >;     /* in zephyr\dts\arm\st\u5\stm32u5.dtsi:698 */
			resets = < &rctl 0xf8d >;       /* in zephyr\dts\arm\st\u5\stm32u5.dtsi:700 */
			interrupts = < 0x33 0x0 >,
			             < 0x34 0x0 >,
			             < 0x35 0x0 >,
			             < 0x36 0x0 >;      /* in zephyr\dts\arm\st\u5\stm32u5.dtsi:701 */
			interrupt-names = "brk",
			                  "up",
			                  "trgcom",
			                  "cc";         /* in zephyr\dts\arm\st\u5\stm32u5.dtsi:702 */
			status = "disabled";            /* in zephyr\dts\arm\st\u5\stm32u5.dtsi:703 */

			/* node '/soc/timers@40013400/pwm' defined in zephyr\dts\arm\st\u5\stm32u5.dtsi:705 */
			pwm {
				compatible = "st,stm32-pwm"; /* in zephyr\dts\arm\st\u5\stm32u5.dtsi:706 */
				status = "disabled";         /* in zephyr\dts\arm\st\u5\stm32u5.dtsi:707 */
				#pwm-cells = < 0x3 >;        /* in zephyr\dts\arm\st\u5\stm32u5.dtsi:708 */
			};

			/* node '/soc/timers@40013400/counter' defined in zephyr\dts\arm\st\u5\stm32u5.dtsi:711 */
			counter {
				compatible = "st,stm32-counter"; /* in zephyr\dts\arm\st\u5\stm32u5.dtsi:712 */
				status = "disabled";             /* in zephyr\dts\arm\st\u5\stm32u5.dtsi:713 */
			};

			/* node '/soc/timers@40013400/qdec' defined in zephyr\dts\arm\st\u5\stm32u5.dtsi:716 */
			qdec {
				compatible = "st,stm32-qdec";    /* in zephyr\dts\arm\st\u5\stm32u5.dtsi:717 */
				st,input-filter-level = < 0x0 >; /* in zephyr\dts\arm\st\u5\stm32u5.dtsi:718 */
				status = "disabled";             /* in zephyr\dts\arm\st\u5\stm32u5.dtsi:719 */
			};
		};

		/* node '/soc/timers@40014000' defined in zephyr\dts\arm\st\u5\stm32u5.dtsi:723 */
		timers15: timers@40014000 {
			compatible = "st,stm32-timers"; /* in zephyr\dts\arm\st\u5\stm32u5.dtsi:724 */
			reg = < 0x40014000 0x400 >;     /* in zephyr\dts\arm\st\u5\stm32u5.dtsi:725 */
			clocks = < &rcc 0xa4 0x10000 >,
			         < &rcc 0xe 0xff >;     /* in zephyr\dts\arm\st\u5\stm32u5.dtsi:726 */
			resets = < &rctl 0xf90 >;       /* in zephyr\dts\arm\st\u5\stm32u5.dtsi:728 */
			interrupts = < 0x45 0x0 >;      /* in zephyr\dts\arm\st\u5\stm32u5.dtsi:729 */
			interrupt-names = "global";     /* in zephyr\dts\arm\st\u5\stm32u5.dtsi:730 */
			status = "disabled";            /* in zephyr\dts\arm\st\u5\stm32u5.dtsi:731 */

			/* node '/soc/timers@40014000/pwm' defined in zephyr\dts\arm\st\u5\stm32u5.dtsi:733 */
			pwm {
				compatible = "st,stm32-pwm"; /* in zephyr\dts\arm\st\u5\stm32u5.dtsi:734 */
				status = "disabled";         /* in zephyr\dts\arm\st\u5\stm32u5.dtsi:735 */
				#pwm-cells = < 0x3 >;        /* in zephyr\dts\arm\st\u5\stm32u5.dtsi:736 */
			};

			/* node '/soc/timers@40014000/counter' defined in zephyr\dts\arm\st\u5\stm32u5.dtsi:739 */
			counter {
				compatible = "st,stm32-counter"; /* in zephyr\dts\arm\st\u5\stm32u5.dtsi:740 */
				status = "disabled";             /* in zephyr\dts\arm\st\u5\stm32u5.dtsi:741 */
			};
		};

		/* node '/soc/timers@40014400' defined in zephyr\dts\arm\st\u5\stm32u5.dtsi:745 */
		timers16: timers@40014400 {
			compatible = "st,stm32-timers"; /* in zephyr\dts\arm\st\u5\stm32u5.dtsi:746 */
			reg = < 0x40014400 0x400 >;     /* in zephyr\dts\arm\st\u5\stm32u5.dtsi:747 */
			clocks = < &rcc 0xa4 0x20000 >,
			         < &rcc 0xe 0xff >;     /* in zephyr\dts\arm\st\u5\stm32u5.dtsi:748 */
			resets = < &rctl 0xf91 >;       /* in zephyr\dts\arm\st\u5\stm32u5.dtsi:750 */
			interrupts = < 0x46 0x0 >;      /* in zephyr\dts\arm\st\u5\stm32u5.dtsi:751 */
			interrupt-names = "global";     /* in zephyr\dts\arm\st\u5\stm32u5.dtsi:752 */
			status = "disabled";            /* in zephyr\dts\arm\st\u5\stm32u5.dtsi:753 */

			/* node '/soc/timers@40014400/pwm' defined in zephyr\dts\arm\st\u5\stm32u5.dtsi:755 */
			pwm {
				compatible = "st,stm32-pwm"; /* in zephyr\dts\arm\st\u5\stm32u5.dtsi:756 */
				status = "disabled";         /* in zephyr\dts\arm\st\u5\stm32u5.dtsi:757 */
				#pwm-cells = < 0x3 >;        /* in zephyr\dts\arm\st\u5\stm32u5.dtsi:758 */
			};

			/* node '/soc/timers@40014400/counter' defined in zephyr\dts\arm\st\u5\stm32u5.dtsi:761 */
			counter {
				compatible = "st,stm32-counter"; /* in zephyr\dts\arm\st\u5\stm32u5.dtsi:762 */
				status = "disabled";             /* in zephyr\dts\arm\st\u5\stm32u5.dtsi:763 */
			};
		};

		/* node '/soc/timers@40014800' defined in zephyr\dts\arm\st\u5\stm32u5.dtsi:767 */
		timers17: timers@40014800 {
			compatible = "st,stm32-timers"; /* in zephyr\dts\arm\st\u5\stm32u5.dtsi:768 */
			reg = < 0x40014800 0x400 >;     /* in zephyr\dts\arm\st\u5\stm32u5.dtsi:769 */
			clocks = < &rcc 0xa4 0x40000 >,
			         < &rcc 0xe 0xff >;     /* in zephyr\dts\arm\st\u5\stm32u5.dtsi:770 */
			resets = < &rctl 0xf92 >;       /* in zephyr\dts\arm\st\u5\stm32u5.dtsi:772 */
			interrupts = < 0x47 0x0 >;      /* in zephyr\dts\arm\st\u5\stm32u5.dtsi:773 */
			interrupt-names = "global";     /* in zephyr\dts\arm\st\u5\stm32u5.dtsi:774 */
			status = "disabled";            /* in zephyr\dts\arm\st\u5\stm32u5.dtsi:775 */

			/* node '/soc/timers@40014800/pwm' defined in zephyr\dts\arm\st\u5\stm32u5.dtsi:777 */
			pwm {
				compatible = "st,stm32-pwm"; /* in zephyr\dts\arm\st\u5\stm32u5.dtsi:778 */
				status = "disabled";         /* in zephyr\dts\arm\st\u5\stm32u5.dtsi:779 */
				#pwm-cells = < 0x3 >;        /* in zephyr\dts\arm\st\u5\stm32u5.dtsi:780 */
			};

			/* node '/soc/timers@40014800/counter' defined in zephyr\dts\arm\st\u5\stm32u5.dtsi:783 */
			counter {
				compatible = "st,stm32-counter"; /* in zephyr\dts\arm\st\u5\stm32u5.dtsi:784 */
				status = "disabled";             /* in zephyr\dts\arm\st\u5\stm32u5.dtsi:785 */
			};
		};

		/* node '/soc/spi@420d1400' defined in zephyr\dts\arm\st\u5\stm32u5.dtsi:789 */
		octospi1: spi@420d1400 {
			compatible = "st,stm32-ospi";    /* in zephyr\dts\arm\st\u5\stm32u5.dtsi:790 */
			reg = < 0x420d1400 0x400 >,
			      < 0x90000000 0x10000000 >; /* in zephyr\dts\arm\st\u5\stm32u5.dtsi:791 */
			interrupts = < 0x4c 0x0 >;       /* in zephyr\dts\arm\st\u5\stm32u5.dtsi:792 */
			clock-names = "ospix",
			              "ospi-ker",
			              "ospi-mgr";        /* in zephyr\dts\arm\st\u5\stm32u5.dtsi:793 */
			clocks = < &rcc 0x90 0x10 >,
			         < &rcc 0x1 0x3400e4 >,
			         < &rcc 0x8c 0x200000 >; /* in zephyr\dts\arm\st\u5\stm32u5.dtsi:794 */
			#address-cells = < 0x1 >;        /* in zephyr\dts\arm\st\u5\stm32u5.dtsi:797 */
			#size-cells = < 0x0 >;           /* in zephyr\dts\arm\st\u5\stm32u5.dtsi:798 */
			status = "disabled";             /* in zephyr\dts\arm\st\u5\stm32u5.dtsi:799 */
		};

		/* node '/soc/spi@420d2400' defined in zephyr\dts\arm\st\u5\stm32u5.dtsi:802 */
		octospi2: spi@420d2400 {
			compatible = "st,stm32-ospi";    /* in zephyr\dts\arm\st\u5\stm32u5_extra.dtsi:59 */
			reg = < 0x420d2400 0x400 >,
			      < 0x70000000 0x10000000 >; /* in zephyr\dts\arm\st\u5\stm32u5_extra.dtsi:60 */
			interrupts = < 0x78 0x0 >;       /* in zephyr\dts\arm\st\u5\stm32u5_extra.dtsi:61 */
			clock-names = "ospix",
			              "ospi-ker",
			              "ospi-mgr";        /* in zephyr\dts\arm\st\u5\stm32u5_extra.dtsi:62 */
			clocks = < &rcc 0x90 0x100 >,
			         < &rcc 0x1 0x3400e4 >,
			         < &rcc 0x8c 0x200000 >; /* in zephyr\dts\arm\st\u5\stm32u5_extra.dtsi:63 */
			#address-cells = < 0x1 >;        /* in zephyr\dts\arm\st\u5\stm32u5_extra.dtsi:66 */
			#size-cells = < 0x0 >;           /* in zephyr\dts\arm\st\u5\stm32u5_extra.dtsi:67 */
			status = "disabled";             /* in zephyr\dts\arm\st\u5\stm32u5_extra.dtsi:68 */
		};

		/* node '/soc/rng@420c0800' defined in zephyr\dts\arm\st\u5\stm32u5.dtsi:815 */
		rng: rng@420c0800 {
			compatible = "st,stm32-rng";     /* in zephyr\dts\arm\st\u5\stm32u5.dtsi:816 */
			reg = < 0x420c0800 0x400 >;      /* in zephyr\dts\arm\st\u5\stm32u5.dtsi:817 */
			clocks = < &rcc 0x8c 0x40000 >;  /* in zephyr\dts\arm\st\u5\stm32u5.dtsi:818 */
			interrupts = < 0x5e 0x0 >;       /* in zephyr\dts\arm\st\u5\stm32u5.dtsi:819 */
			nist-config = < 0xf60d00 >;      /* in zephyr\dts\arm\st\u5\stm32u5.dtsi:820 */
			health-test-config = < 0x9aae >; /* in zephyr\dts\arm\st\u5\stm32u5.dtsi:821 */
			status = "okay";                 /* in zephyr\boards\st\nucleo_u5a5zj_q\nucleo_u5a5zj_q-common.dtsi:176 */
		};

		/* node '/soc/sdmmc@420c8000' defined in zephyr\dts\arm\st\u5\stm32u5.dtsi:834 */
		sdmmc1: sdmmc@420c8000 {
			compatible = "st,stm32-sdmmc";                                                                                 /* in zephyr\dts\arm\st\u5\stm32u5.dtsi:835 */
			reg = < 0x420c8000 0x400 >;                                                                                    /* in zephyr\dts\arm\st\u5\stm32u5.dtsi:836 */
			clocks = < &rcc 0x8c 0x8000000 >,
			         < &rcc 0x6 0xe00e4 >;                                                                                 /* in zephyr\dts\arm\st\u5\stm32u5.dtsi:837 */
			resets = < &rctl 0xc9b >;                                                                                      /* in zephyr\dts\arm\st\u5\stm32u5.dtsi:839 */
			interrupts = < 0x4e 0x0 >;                                                                                     /* in zephyr\dts\arm\st\u5\stm32u5.dtsi:840 */
			status = "okay";                                                                                               /* in boards\nucleo_u5a5zj_q.overlay:18 */
			pinctrl-0 = < &sdmmc1_d0_pc8 &sdmmc1_d1_pc9 &sdmmc1_d2_pc10 &sdmmc1_d3_pc11 &sdmmc1_ck_pc12 &sdmmc1_cmd_pd2 >; /* in boards\nucleo_u5a5zj_q.overlay:19 */
			pinctrl-names = "default";                                                                                     /* in boards\nucleo_u5a5zj_q.overlay:20 */
			disk-name = "SD";                                                                                              /* in boards\nucleo_u5a5zj_q.overlay:21 */
			bus-width = < 0x4 >;                                                                                           /* in boards\nucleo_u5a5zj_q.overlay:22 */
		};

		/* node '/soc/dac@46021800' defined in zephyr\dts\arm\st\u5\stm32u5.dtsi:844 */
		dac1: dac@46021800 {
			compatible = "st,stm32-dac";    /* in zephyr\dts\arm\st\u5\stm32u5.dtsi:845 */
			reg = < 0x46021800 0x400 >;     /* in zephyr\dts\arm\st\u5\stm32u5.dtsi:846 */
			clocks = < &rcc 0x94 0x40 >;    /* in zephyr\dts\arm\st\u5\stm32u5.dtsi:847 */
			#io-channel-cells = < 0x1 >;    /* in zephyr\dts\arm\st\u5\stm32u5.dtsi:849 */
			pinctrl-0 = < &dac1_out1_pa4 >; /* in zephyr\boards\st\nucleo_u5a5zj_q\nucleo_u5a5zj_q-common.dtsi:128 */
			pinctrl-names = "default";      /* in zephyr\boards\st\nucleo_u5a5zj_q\nucleo_u5a5zj_q-common.dtsi:129 */
			status = "okay";                /* in zephyr\boards\st\nucleo_u5a5zj_q\nucleo_u5a5zj_q-common.dtsi:130 */
		};

		/* node '/soc/adc@42028000' defined in zephyr\dts\arm\st\u5\stm32u5.dtsi:852 */
		adc1: adc@42028000 {
			compatible = "st,stm32-adc";                                 /* in zephyr\dts\arm\st\u5\stm32u5.dtsi:853 */
			reg = < 0x42028000 0x400 >;                                  /* in zephyr\dts\arm\st\u5\stm32u5.dtsi:854 */
			clocks = < &rcc 0x8c 0x400 >,
			         < &rcc 0x9 0x4c00e8 >;                              /* in zephyr\dts\arm\st\u5\stm32u5.dtsi:855 */
			clock-names = "adcx",
			              "adc_ker";                                     /* in zephyr\dts\arm\st\u5\stm32u5.dtsi:857 */
			interrupts = < 0x25 0x0 >;                                   /* in zephyr\dts\arm\st\u5\stm32u5.dtsi:858 */
			#io-channel-cells = < 0x1 >;                                 /* in zephyr\dts\arm\st\u5\stm32u5.dtsi:859 */
			resolutions = < 0x70620c 0x61620c 0x52620c 0x43620c >;       /* in zephyr\dts\arm\st\u5\stm32u5.dtsi:860 */
			sampling-times = < 0x5 0x6 0xc 0x14 0x24 0x44 0x187 0x32e >; /* in zephyr\dts\arm\st\u5\stm32u5.dtsi:864 */
			st,adc-sequencer = "programmable";                           /* in zephyr\dts\arm\st\u5\stm32u5.dtsi:866 */
			st,adc-oversampler = "extended";                             /* in zephyr\dts\arm\st\u5\stm32u5.dtsi:867 */
			st,adc-internal-regulator = "startup-hw-status";             /* in zephyr\dts\arm\st\u5\stm32u5.dtsi:868 */
			st,adc-has-deep-powerdown;                                   /* in zephyr\dts\arm\st\u5\stm32u5.dtsi:869 */
			st,adc-has-channel-preselection;                             /* in zephyr\dts\arm\st\u5\stm32u5.dtsi:870 */
			st,adc-has-differential-support;                             /* in zephyr\dts\arm\st\u5\stm32u5.dtsi:871 */
			pinctrl-0 = < &adc1_in1_pc0 >;                               /* in zephyr\boards\st\nucleo_u5a5zj_q\nucleo_u5a5zj_q-common.dtsi:134 */
			pinctrl-names = "default";                                   /* in zephyr\boards\st\nucleo_u5a5zj_q\nucleo_u5a5zj_q-common.dtsi:135 */
			st,adc-clock-source = "ASYNC";                               /* in zephyr\boards\st\nucleo_u5a5zj_q\nucleo_u5a5zj_q-common.dtsi:136 */
			st,adc-prescaler = < 0x4 >;                                  /* in zephyr\boards\st\nucleo_u5a5zj_q\nucleo_u5a5zj_q-common.dtsi:137 */
			status = "okay";                                             /* in zephyr\boards\st\nucleo_u5a5zj_q\nucleo_u5a5zj_q-common.dtsi:138 */
			phandle = < 0x37 >;                                          /* in zephyr\dts\arm\st\u5\stm32u5.dtsi:1032 */
		};

		/* node '/soc/adc@46021000' defined in zephyr\dts\arm\st\u5\stm32u5.dtsi:875 */
		adc4: adc@46021000 {
			compatible = "st,stm32-adc";                               /* in zephyr\dts\arm\st\u5\stm32u5.dtsi:876 */
			reg = < 0x46021000 0x400 >;                                /* in zephyr\dts\arm\st\u5\stm32u5.dtsi:877 */
			clocks = < &rcc 0x94 0x20 >,
			         < &rcc 0x9 0x4c00e8 >;                            /* in zephyr\dts\arm\st\u5\stm32u5.dtsi:878 */
			clock-names = "adcx",
			              "adc_ker";                                   /* in zephyr\dts\arm\st\u5\stm32u5.dtsi:880 */
			interrupts = < 0x71 0x0 >;                                 /* in zephyr\dts\arm\st\u5\stm32u5.dtsi:881 */
			#io-channel-cells = < 0x1 >;                               /* in zephyr\dts\arm\st\u5\stm32u5.dtsi:882 */
			resolutions = < 0x60620c 0x51620c 0x42620c 0x33620c >;     /* in zephyr\dts\arm\st\u5\stm32u5.dtsi:883 */
			sampling-times = < 0x2 0x4 0x8 0xd 0x14 0x28 0x50 0x32f >; /* in zephyr\dts\arm\st\u5\stm32u5.dtsi:887 */
			num-sampling-time-common-channels = < 0x2 >;               /* in zephyr\dts\arm\st\u5\stm32u5.dtsi:888 */
			st,adc-sequencer = "fixed";                                /* in zephyr\dts\arm\st\u5\stm32u5.dtsi:890 */
			st,adc-oversampler = "minimal";                            /* in zephyr\dts\arm\st\u5\stm32u5.dtsi:891 */
			st,adc-internal-regulator = "startup-hw-status";           /* in zephyr\dts\arm\st\u5\stm32u5.dtsi:892 */
			pinctrl-0 = < &adc4_in18_pb0 >;                            /* in zephyr\boards\st\nucleo_u5a5zj_q\nucleo_u5a5zj_q-common.dtsi:142 */
			pinctrl-names = "default";                                 /* in zephyr\boards\st\nucleo_u5a5zj_q\nucleo_u5a5zj_q-common.dtsi:143 */
			st,adc-clock-source = "ASYNC";                             /* in zephyr\boards\st\nucleo_u5a5zj_q\nucleo_u5a5zj_q-common.dtsi:144 */
			st,adc-prescaler = < 0x4 >;                                /* in zephyr\boards\st\nucleo_u5a5zj_q\nucleo_u5a5zj_q-common.dtsi:145 */
			status = "okay";                                           /* in zephyr\boards\st\nucleo_u5a5zj_q\nucleo_u5a5zj_q-common.dtsi:146 */
			phandle = < 0x38 >;                                        /* in zephyr\dts\arm\st\u5\stm32u5.dtsi:1050 */
		};

		/* node '/soc/can@4000a400' defined in zephyr\dts\arm\st\u5\stm32u5.dtsi:896 */
		fdcan1: can@4000a400 {
			compatible = "st,stm32-fdcan";                         /* in zephyr\dts\arm\st\u5\stm32u5.dtsi:897 */
			reg = < 0x4000a400 0x400 >,
			      < 0x4000ac00 0x350 >;                            /* in zephyr\dts\arm\st\u5\stm32u5.dtsi:898 */
			reg-names = "m_can",
			            "message_ram";                             /* in zephyr\dts\arm\st\u5\stm32u5.dtsi:899 */
			interrupts = < 0x27 0x0 >,
			             < 0x28 0x0 >;                             /* in zephyr\dts\arm\st\u5\stm32u5.dtsi:900 */
			interrupt-names = "int0",
			                  "int1";                              /* in zephyr\dts\arm\st\u5\stm32u5.dtsi:901 */
			bosch,mram-cfg = < 0x0 0x1c 0x8 0x3 0x3 0x0 0x3 0x3 >; /* in zephyr\dts\arm\st\u5\stm32u5.dtsi:903 */
			clocks = < &rcc 0xa0 0x200 >,
			         < &rcc 0x10 0x13800e0 >;                      /* in zephyr\boards\st\nucleo_u5a5zj_q\nucleo_u5a5zj_q-common.dtsi:180 */
			pinctrl-0 = < &fdcan1_rx_pd0 &fdcan1_tx_pd1 >;         /* in zephyr\boards\st\nucleo_u5a5zj_q\nucleo_u5a5zj_q-common.dtsi:182 */
			pinctrl-names = "default";                             /* in zephyr\boards\st\nucleo_u5a5zj_q\nucleo_u5a5zj_q-common.dtsi:183 */
			status = "okay";                                       /* in zephyr\boards\st\nucleo_u5a5zj_q\nucleo_u5a5zj_q-common.dtsi:184 */
		};

		/* node '/soc/dma@40020000' defined in zephyr\dts\arm\st\u5\stm32u5.dtsi:907 */
		gpdma1: dma@40020000 {
			compatible = "st,stm32u5-dma";                                                                  /* in zephyr\dts\arm\st\u5\stm32u5.dtsi:908 */
			#dma-cells = < 0x3 >;                                                                           /* in zephyr\dts\arm\st\u5\stm32u5.dtsi:909 */
			reg = < 0x40020000 0x400 >;                                                                     /* in zephyr\dts\arm\st\u5\stm32u5.dtsi:910 */
			interrupts = < 0x1d 0x0 0x1e 0x0 0x1f 0x0 0x20 0x0 0x21 0x0 0x22 0x0 0x23 0x0 0x24 0x0 0x50 0x0
			               0x51 0x0 0x52 0x0 0x53 0x0 0x54 0x0 0x55 0x0 0x56 0x0 0x57 0x0 >;                /* in zephyr\dts\arm\st\u5\stm32u5.dtsi:911 */
			clocks = < &rcc 0x88 0x1 >;                                                                     /* in zephyr\dts\arm\st\u5\stm32u5.dtsi:913 */
			dma-channels = < 0x10 >;                                                                        /* in zephyr\dts\arm\st\u5\stm32u5.dtsi:914 */
			dma-requests = < 0x72 >;                                                                        /* in zephyr\dts\arm\st\u5\stm32u5.dtsi:915 */
			dma-offset = < 0x0 >;                                                                           /* in zephyr\dts\arm\st\u5\stm32u5.dtsi:916 */
			status = "okay";                                                                                /* in zephyr\boards\st\nucleo_u5a5zj_q\nucleo_u5a5zj_q.dts:77 */
			phandle = < 0x11 >;                                                                             /* in zephyr\dts\arm\st\u5\stm32u5.dtsi:494 */
		};

		/* node '/soc/hash@420c0400' defined in zephyr\dts\arm\st\u5\stm32u5.dtsi:920 */
		hash: hash@420c0400 {
			compatible = "st,stm32-hash";   /* in zephyr\dts\arm\st\u5\stm32u5.dtsi:921 */
			reg = < 0x420c0400 0x400 >;     /* in zephyr\dts\arm\st\u5\stm32u5.dtsi:922 */
			clocks = < &rcc 0x8c 0x20000 >; /* in zephyr\dts\arm\st\u5\stm32u5.dtsi:923 */
			resets = < &rctl 0xc91 >;       /* in zephyr\dts\arm\st\u5\stm32u5.dtsi:924 */
			status = "disabled";            /* in zephyr\dts\arm\st\u5\stm32u5.dtsi:925 */
		};

		/* node '/soc/vrefbuf@46007400' defined in zephyr\dts\arm\st\u5\stm32u5.dtsi:928 */
		vrefbuf: vrefbuf@46007400 {
			compatible = "st,stm32-vrefbuf"; /* in zephyr\dts\arm\st\u5\stm32u5.dtsi:929 */
			reg = < 0x46007400 0x400 >;      /* in zephyr\dts\arm\st\u5\stm32u5.dtsi:930 */
			clocks = < &rcc 0xa8 0x100000 >; /* in zephyr\dts\arm\st\u5\stm32u5.dtsi:931 */
			resets = < &rctl 0x1014 >;       /* in zephyr\dts\arm\st\u5\stm32u5.dtsi:932 */
			ref-voltages = < 0x16e360 >,
			               < 0x1b7740 >,
			               < 0x1f4000 >,
			               < 0x2625a0 >;     /* in zephyr\dts\arm\st\u5\stm32u5.dtsi:933 */
			status = "disabled";             /* in zephyr\dts\arm\st\u5\stm32u5.dtsi:934 */
		};

		/* node '/soc/power@46020800' defined in zephyr\dts\arm\st\u5\stm32u5.dtsi:937 */
		pwr: power@46020800 {
			compatible = "st,stm32u5-pwr",
			             "st,stm32-dualreg-pwr",
			             "st,stm32-pwr";         /* in zephyr\dts\arm\st\u5\stm32u5.dtsi:938 */
			reg = < 0x46020800 0x400 >;          /* in zephyr\dts\arm\st\u5\stm32u5.dtsi:939 */
			status = "disabled";                 /* in zephyr\dts\arm\st\u5\stm32u5.dtsi:940 */
			power-supply = "ldo";                /* in zephyr\dts\arm\st\u5\stm32u5.dtsi:947 */
			wkup-pins-nb = < 0x8 >;              /* in zephyr\dts\arm\st\u5\stm32u5.dtsi:949 */
			wkup-pin-srcs = < 0x3 >;             /* in zephyr\dts\arm\st\u5\stm32u5.dtsi:950 */
			wkup-pins-pol;                       /* in zephyr\dts\arm\st\u5\stm32u5.dtsi:951 */
			wkup-pins-pupd;                      /* in zephyr\dts\arm\st\u5\stm32u5.dtsi:952 */
			#address-cells = < 0x1 >;            /* in zephyr\dts\arm\st\u5\stm32u5.dtsi:954 */
			#size-cells = < 0x0 >;               /* in zephyr\dts\arm\st\u5\stm32u5.dtsi:955 */

			/* node '/soc/power@46020800/wkup-pin@1' defined in zephyr\dts\arm\st\u5\stm32u5.dtsi:957 */
			wkup-pin@1 {
				reg = < 0x1 >;                   /* in zephyr\dts\arm\st\u5\stm32u5.dtsi:958 */
				wkup-gpios = < &gpioa 0x0 0x1 >,
				             < &gpiob 0x2 0x2 >,
				             < &gpioe 0x4 0x4 >; /* in zephyr\dts\arm\st\u5\stm32u5.dtsi:959 */
			};

			/* node '/soc/power@46020800/wkup-pin@2' defined in zephyr\dts\arm\st\u5\stm32u5.dtsi:964 */
			wkup-pin@2 {
				reg = < 0x2 >;                   /* in zephyr\dts\arm\st\u5\stm32u5.dtsi:965 */
				wkup-gpios = < &gpioa 0x4 0x1 >,
				             < &gpioc 0xd 0x2 >,
				             < &gpioe 0x5 0x4 >; /* in zephyr\dts\arm\st\u5\stm32u5.dtsi:966 */
			};

			/* node '/soc/power@46020800/wkup-pin@3' defined in zephyr\dts\arm\st\u5\stm32u5.dtsi:971 */
			wkup-pin@3 {
				reg = < 0x3 >;                   /* in zephyr\dts\arm\st\u5\stm32u5.dtsi:972 */
				wkup-gpios = < &gpioe 0x6 0x1 >,
				             < &gpioa 0x1 0x2 >,
				             < &gpiob 0x6 0x4 >; /* in zephyr\dts\arm\st\u5\stm32u5.dtsi:973 */
			};

			/* node '/soc/power@46020800/wkup-pin@4' defined in zephyr\dts\arm\st\u5\stm32u5.dtsi:978 */
			wkup-pin@4 {
				reg = < 0x4 >;                   /* in zephyr\dts\arm\st\u5\stm32u5.dtsi:979 */
				wkup-gpios = < &gpioa 0x2 0x1 >,
				             < &gpiob 0x1 0x2 >,
				             < &gpiob 0x7 0x4 >; /* in zephyr\dts\arm\st\u5\stm32u5.dtsi:980 */
			};

			/* node '/soc/power@46020800/wkup-pin@5' defined in zephyr\dts\arm\st\u5\stm32u5.dtsi:985 */
			wkup-pin@5 {
				reg = < 0x5 >;                   /* in zephyr\dts\arm\st\u5\stm32u5.dtsi:986 */
				wkup-gpios = < &gpioc 0x5 0x1 >,
				             < &gpioa 0x3 0x2 >,
				             < &gpiob 0x8 0x4 >; /* in zephyr\dts\arm\st\u5\stm32u5.dtsi:987 */
			};

			/* node '/soc/power@46020800/wkup-pin@6' defined in zephyr\dts\arm\st\u5\stm32u5.dtsi:992 */
			wkup-pin@6 {
				reg = < 0x6 >;                   /* in zephyr\dts\arm\st\u5\stm32u5.dtsi:993 */
				wkup-gpios = < &gpiob 0x5 0x1 >,
				             < &gpioa 0x5 0x2 >,
				             < &gpioe 0x7 0x4 >; /* in zephyr\dts\arm\st\u5\stm32u5.dtsi:994 */
			};

			/* node '/soc/power@46020800/wkup-pin@7' defined in zephyr\dts\arm\st\u5\stm32u5.dtsi:999 */
			wkup-pin@7 {
				reg = < 0x7 >;                   /* in zephyr\dts\arm\st\u5\stm32u5.dtsi:1000 */
				wkup-gpios = < &gpiob 0xf 0x1 >,
				             < &gpioa 0x6 0x2 >,
				             < &gpioe 0x8 0x4 >; /* in zephyr\dts\arm\st\u5\stm32u5.dtsi:1001 */
			};

			/* node '/soc/power@46020800/wkup-pin@8' defined in zephyr\dts\arm\st\u5\stm32u5.dtsi:1006 */
			wkup-pin@8 {
				reg = < 0x8 >;                   /* in zephyr\dts\arm\st\u5\stm32u5.dtsi:1007 */
				wkup-gpios = < &gpiof 0x2 0x1 >,
				             < &gpioa 0x7 0x2 >,
				             < &gpiob 0xa 0x4 >; /* in zephyr\dts\arm\st\u5\stm32u5_extra.dtsi:83 */
			};
		};

		/* node '/soc/serial@40004400' defined in zephyr\dts\arm\st\u5\stm32u5_extra.dtsi:9 */
		usart2: serial@40004400 {
			compatible = "st,stm32-usart",
			             "st,stm32-uart";                  /* in zephyr\dts\arm\st\u5\stm32u5_extra.dtsi:10 */
			reg = < 0x40004400 0x400 >;                    /* in zephyr\dts\arm\st\u5\stm32u5_extra.dtsi:11 */
			clocks = < &rcc 0x9c 0x20000 >;                /* in zephyr\dts\arm\st\u5\stm32u5_extra.dtsi:12 */
			resets = < &rctl 0xe91 >;                      /* in zephyr\dts\arm\st\u5\stm32u5_extra.dtsi:13 */
			interrupts = < 0x3e 0x0 >;                     /* in zephyr\dts\arm\st\u5\stm32u5_extra.dtsi:14 */
			pinctrl-0 = < &usart2_tx_pd5 &usart2_rx_pd6 >; /* in zephyr\boards\st\nucleo_u5a5zj_q\nucleo_u5a5zj_q-common.dtsi:100 */
			pinctrl-names = "default";                     /* in zephyr\boards\st\nucleo_u5a5zj_q\nucleo_u5a5zj_q-common.dtsi:101 */
			current-speed = < 0x1c200 >;                   /* in zephyr\boards\st\nucleo_u5a5zj_q\nucleo_u5a5zj_q-common.dtsi:102 */
			status = "okay";                               /* in zephyr\boards\st\nucleo_u5a5zj_q\nucleo_u5a5zj_q-common.dtsi:103 */
		};

		/* node '/soc/gpio@42021400' defined in zephyr\dts\arm\st\u5\stm32u5_extra.dtsi:18 */
		gpiof: gpio@42021400 {
			compatible = "st,stm32-gpio"; /* in zephyr\dts\arm\st\u5\stm32u5_extra.dtsi:19 */
			gpio-controller;              /* in zephyr\dts\arm\st\u5\stm32u5_extra.dtsi:20 */
			#gpio-cells = < 0x2 >;        /* in zephyr\dts\arm\st\u5\stm32u5_extra.dtsi:21 */
			reg = < 0x42021400 0x400 >;   /* in zephyr\dts\arm\st\u5\stm32u5_extra.dtsi:22 */
			clocks = < &rcc 0x8c 0x20 >;  /* in zephyr\dts\arm\st\u5\stm32u5_extra.dtsi:23 */
			phandle = < 0x23 >;           /* in zephyr\dts\arm\st\u5\stm32u5_extra.dtsi:83 */
		};

		/* node '/soc/gpio@42022000' defined in zephyr\dts\arm\st\u5\stm32u5_extra.dtsi:26 */
		gpioi: gpio@42022000 {
			compatible = "st,stm32-gpio"; /* in zephyr\dts\arm\st\u5\stm32u5_extra.dtsi:27 */
			gpio-controller;              /* in zephyr\dts\arm\st\u5\stm32u5_extra.dtsi:28 */
			#gpio-cells = < 0x2 >;        /* in zephyr\dts\arm\st\u5\stm32u5_extra.dtsi:29 */
			reg = < 0x42022000 0x400 >;   /* in zephyr\dts\arm\st\u5\stm32u5_extra.dtsi:30 */
			clocks = < &rcc 0x8c 0x100 >; /* in zephyr\dts\arm\st\u5\stm32u5_extra.dtsi:31 */
		};

		/* node '/soc/sdmmc@420c8c00' defined in zephyr\dts\arm\st\u5\stm32u5_extra.dtsi:34 */
		sdmmc2: sdmmc@420c8c00 {
			compatible = "st,stm32-sdmmc";     /* in zephyr\dts\arm\st\u5\stm32u5_extra.dtsi:35 */
			reg = < 0x420c8c00 0x400 >;        /* in zephyr\dts\arm\st\u5\stm32u5_extra.dtsi:36 */
			clocks = < &rcc 0x8c 0x10000000 >,
			         < &rcc 0x6 0xe00e4 >;     /* in zephyr\dts\arm\st\u5\stm32u5_extra.dtsi:37 */
			resets = < &rctl 0xc9c >;          /* in zephyr\dts\arm\st\u5\stm32u5_extra.dtsi:39 */
			interrupts = < 0x4f 0x0 >;         /* in zephyr\dts\arm\st\u5\stm32u5_extra.dtsi:40 */
			status = "disabled";               /* in zephyr\dts\arm\st\u5\stm32u5_extra.dtsi:41 */
		};

		/* node '/soc/memory-controller@420d0400' defined in zephyr\dts\arm\st\u5\stm32u5_extra.dtsi:44 */
		fmc: memory-controller@420d0400 {
			compatible = "st,stm32-fmc"; /* in zephyr\dts\arm\st\u5\stm32u5_extra.dtsi:45 */
			reg = < 0x420d0400 0x400 >;  /* in zephyr\dts\arm\st\u5\stm32u5_extra.dtsi:46 */
			clocks = < &rcc 0x90 0x1 >;  /* in zephyr\dts\arm\st\u5\stm32u5_extra.dtsi:47 */
			status = "disabled";         /* in zephyr\dts\arm\st\u5\stm32u5_extra.dtsi:48 */

			/* node '/soc/memory-controller@420d0400/sram' defined in zephyr\dts\arm\st\u5\stm32u5_extra.dtsi:50 */
			sram {
				compatible = "st,stm32-fmc-nor-psram"; /* in zephyr\dts\arm\st\u5\stm32u5_extra.dtsi:51 */
				#address-cells = < 0x1 >;              /* in zephyr\dts\arm\st\u5\stm32u5_extra.dtsi:52 */
				#size-cells = < 0x0 >;                 /* in zephyr\dts\arm\st\u5\stm32u5_extra.dtsi:53 */
				status = "disabled";                   /* in zephyr\dts\arm\st\u5\stm32u5_extra.dtsi:54 */
			};
		};

		/* node '/soc/ucpd@4000dc00' defined in zephyr\dts\arm\st\u5\stm32u5_extra.dtsi:71 */
		ucpd1: ucpd@4000dc00 {
			compatible = "st,stm32-ucpd";    /* in zephyr\dts\arm\st\u5\stm32u5_extra.dtsi:72 */
			reg = < 0x4000dc00 0x400 >;      /* in zephyr\dts\arm\st\u5\stm32u5_extra.dtsi:73 */
			clocks = < &rcc 0x9c 0x800000 >; /* in zephyr\dts\arm\st\u5\stm32u5_extra.dtsi:74 */
			interrupts = < 0x6a 0x0 >;       /* in zephyr\dts\arm\st\u5\stm32u5_extra.dtsi:75 */
			status = "disabled";             /* in zephyr\dts\arm\st\u5\stm32u5_extra.dtsi:76 */
		};

		/* node '/soc/otghs@42040000' defined in zephyr\dts\arm\st\u5\stm32u5_usbotg_hs.dtsi:12 */
		usbotg_hs: zephyr_udc0: otghs@42040000 {
			compatible = "st,stm32-otghs";                           /* in zephyr\dts\arm\st\u5\stm32u5_usbotg_hs.dtsi:13 */
			reg = < 0x42040000 0x20000 >;                            /* in zephyr\dts\arm\st\u5\stm32u5_usbotg_hs.dtsi:14 */
			interrupts = < 0x49 0x0 >;                               /* in zephyr\dts\arm\st\u5\stm32u5_usbotg_hs.dtsi:15 */
			interrupt-names = "otghs";                               /* in zephyr\dts\arm\st\u5\stm32u5_usbotg_hs.dtsi:16 */
			num-bidir-endpoints = < 0x9 >;                           /* in zephyr\dts\arm\st\u5\stm32u5_usbotg_hs.dtsi:17 */
			ram-size = < 0x1000 >;                                   /* in zephyr\dts\arm\st\u5\stm32u5_usbotg_hs.dtsi:18 */
			maximum-speed = "high-speed";                            /* in zephyr\dts\arm\st\u5\stm32u5_usbotg_hs.dtsi:19 */
			clocks = < &rcc 0x8c 0x4000 >;                           /* in zephyr\dts\arm\st\u5\stm32u5_usbotg_hs.dtsi:20 */
			phys = < &otghs_phy >;                                   /* in zephyr\dts\arm\st\u5\stm32u5_usbotg_hs.dtsi:21 */
			pinctrl-0 = < &usb_otg_hs_dm_pa11 &usb_otg_hs_dp_pa12 >; /* in zephyr\boards\st\nucleo_u5a5zj_q\nucleo_u5a5zj_q.dts:81 */
			pinctrl-names = "default";                               /* in zephyr\boards\st\nucleo_u5a5zj_q\nucleo_u5a5zj_q.dts:82 */
			status = "okay";                                         /* in boards\nucleo_u5a5zj_q.overlay:26 */
		};

		/* node '/soc/serial@40006400' defined in zephyr\dts\arm\st\u5\stm32u595.dtsi:40 */
		usart6: serial@40006400 {
			compatible = "st,stm32-usart",
			             "st,stm32-uart";     /* in zephyr\dts\arm\st\u5\stm32u595.dtsi:41 */
			reg = < 0x40006400 0x400 >;       /* in zephyr\dts\arm\st\u5\stm32u595.dtsi:42 */
			clocks = < &rcc 0x9c 0x2000000 >; /* in zephyr\dts\arm\st\u5\stm32u595.dtsi:43 */
			resets = < &rctl 0xe99 >;         /* in zephyr\dts\arm\st\u5\stm32u595.dtsi:44 */
			interrupts = < 0x7e 0x0 >;        /* in zephyr\dts\arm\st\u5\stm32u595.dtsi:45 */
			status = "disabled";              /* in zephyr\dts\arm\st\u5\stm32u595.dtsi:46 */
		};

		/* node '/soc/i2c@40009800' defined in zephyr\dts\arm\st\u5\stm32u595.dtsi:49 */
		i2c5: i2c@40009800 {
			compatible = "st,stm32-i2c-v2"; /* in zephyr\dts\arm\st\u5\stm32u595.dtsi:50 */
			clock-frequency = < 0x186a0 >;  /* in zephyr\dts\arm\st\u5\stm32u595.dtsi:51 */
			#address-cells = < 0x1 >;       /* in zephyr\dts\arm\st\u5\stm32u595.dtsi:52 */
			#size-cells = < 0x0 >;          /* in zephyr\dts\arm\st\u5\stm32u595.dtsi:53 */
			reg = < 0x40009800 0x400 >;     /* in zephyr\dts\arm\st\u5\stm32u595.dtsi:54 */
			clocks = < &rcc 0xa0 0x40 >;    /* in zephyr\dts\arm\st\u5\stm32u595.dtsi:55 */
			interrupts = < 0x80 0x0 >,
			             < 0x7f 0x0 >;      /* in zephyr\dts\arm\st\u5\stm32u595.dtsi:56 */
			interrupt-names = "event",
			                  "error";      /* in zephyr\dts\arm\st\u5\stm32u595.dtsi:57 */
			status = "disabled";            /* in zephyr\dts\arm\st\u5\stm32u595.dtsi:58 */
			phandle = < 0x3d >;             /* in zephyr\dts\arm\st\u5\stm32u595.dtsi:129 */
		};

		/* node '/soc/i2c@40009c00' defined in zephyr\dts\arm\st\u5\stm32u595.dtsi:61 */
		i2c6: i2c@40009c00 {
			compatible = "st,stm32-i2c-v2"; /* in zephyr\dts\arm\st\u5\stm32u595.dtsi:62 */
			clock-frequency = < 0x186a0 >;  /* in zephyr\dts\arm\st\u5\stm32u595.dtsi:63 */
			#address-cells = < 0x1 >;       /* in zephyr\dts\arm\st\u5\stm32u595.dtsi:64 */
			#size-cells = < 0x0 >;          /* in zephyr\dts\arm\st\u5\stm32u595.dtsi:65 */
			reg = < 0x40009c00 0x400 >;     /* in zephyr\dts\arm\st\u5\stm32u595.dtsi:66 */
			clocks = < &rcc 0xa0 0x80 >;    /* in zephyr\dts\arm\st\u5\stm32u595.dtsi:67 */
			interrupts = < 0x82 0x0 >,
			             < 0x81 0x0 >;      /* in zephyr\dts\arm\st\u5\stm32u595.dtsi:68 */
			interrupt-names = "event",
			                  "error";      /* in zephyr\dts\arm\st\u5\stm32u595.dtsi:69 */
			status = "disabled";            /* in zephyr\dts\arm\st\u5\stm32u595.dtsi:70 */
			phandle = < 0x3e >;             /* in zephyr\dts\arm\st\u5\stm32u595.dtsi:137 */
		};

		/* node '/soc/adc@42028100' defined in zephyr\dts\arm\st\u5\stm32u595.dtsi:74 */
		adc2: adc@42028100 {
			compatible = "st,stm32-adc";                                 /* in zephyr\dts\arm\st\u5\stm32u595.dtsi:75 */
			reg = < 0x42028100 0x400 >;                                  /* in zephyr\dts\arm\st\u5\stm32u595.dtsi:76 */
			clocks = < &rcc 0x8c 0x400 >,
			         < &rcc 0x9 0x4c00e8 >;                              /* in zephyr\dts\arm\st\u5\stm32u595.dtsi:77 */
			clock-names = "adcx",
			              "adc_ker";                                     /* in zephyr\dts\arm\st\u5\stm32u595.dtsi:79 */
			interrupts = < 0x25 0x0 >;                                   /* in zephyr\dts\arm\st\u5\stm32u595.dtsi:80 */
			#io-channel-cells = < 0x1 >;                                 /* in zephyr\dts\arm\st\u5\stm32u595.dtsi:81 */
			resolutions = < 0x70620c 0x61620c 0x52620c 0x43620c >;       /* in zephyr\dts\arm\st\u5\stm32u595.dtsi:82 */
			sampling-times = < 0x5 0x6 0xc 0x14 0x24 0x44 0x187 0x32e >; /* in zephyr\dts\arm\st\u5\stm32u595.dtsi:86 */
			st,adc-clock-source = "ASYNC";                               /* in zephyr\dts\arm\st\u5\stm32u595.dtsi:87 */
			st,adc-sequencer = "programmable";                           /* in zephyr\dts\arm\st\u5\stm32u595.dtsi:88 */
			st,adc-oversampler = "extended";                             /* in zephyr\dts\arm\st\u5\stm32u595.dtsi:89 */
			st,adc-internal-regulator = "startup-hw-status";             /* in zephyr\dts\arm\st\u5\stm32u595.dtsi:90 */
			st,adc-has-deep-powerdown;                                   /* in zephyr\dts\arm\st\u5\stm32u595.dtsi:91 */
			st,adc-has-channel-preselection;                             /* in zephyr\dts\arm\st\u5\stm32u595.dtsi:92 */
			st,adc-has-differential-support;                             /* in zephyr\dts\arm\st\u5\stm32u595.dtsi:93 */
			status = "disabled";                                         /* in zephyr\dts\arm\st\u5\stm32u595.dtsi:94 */
		};

		/* node '/soc/adc@42028300' defined in zephyr\dts\arm\st\u5\stm32u595.dtsi:101 */
		adc1_2: adc@42028300 {
			compatible = "st,stm32-adc";                                 /* in zephyr\dts\arm\st\u5\stm32u595.dtsi:102 */
			reg = < 0x42028300 0x400 >;                                  /* in zephyr\dts\arm\st\u5\stm32u595.dtsi:103 */
			clocks = < &rcc 0x8c 0x400 >,
			         < &rcc 0x9 0x4c00e8 >;                              /* in zephyr\dts\arm\st\u5\stm32u595.dtsi:104 */
			clock-names = "adcx",
			              "adc_ker";                                     /* in zephyr\dts\arm\st\u5\stm32u595.dtsi:106 */
			interrupts = < 0x25 0x0 >;                                   /* in zephyr\dts\arm\st\u5\stm32u595.dtsi:107 */
			#io-channel-cells = < 0x1 >;                                 /* in zephyr\dts\arm\st\u5\stm32u595.dtsi:108 */
			resolutions = < 0x70620c 0x61620c 0x52620c 0x43620c >;       /* in zephyr\dts\arm\st\u5\stm32u595.dtsi:109 */
			sampling-times = < 0x5 0x6 0xc 0x14 0x24 0x44 0x187 0x32e >; /* in zephyr\dts\arm\st\u5\stm32u595.dtsi:113 */
			st,adc-clock-source = "ASYNC";                               /* in zephyr\dts\arm\st\u5\stm32u595.dtsi:114 */
			st,adc-sequencer = "programmable";                           /* in zephyr\dts\arm\st\u5\stm32u595.dtsi:115 */
			st,adc-oversampler = "extended";                             /* in zephyr\dts\arm\st\u5\stm32u595.dtsi:116 */
			st,adc-internal-regulator = "startup-hw-status";             /* in zephyr\dts\arm\st\u5\stm32u595.dtsi:117 */
			st,adc-has-deep-powerdown;                                   /* in zephyr\dts\arm\st\u5\stm32u595.dtsi:118 */
			st,adc-has-channel-preselection;                             /* in zephyr\dts\arm\st\u5\stm32u595.dtsi:119 */
			st,adc-has-differential-support;                             /* in zephyr\dts\arm\st\u5\stm32u595.dtsi:120 */
			status = "disabled";                                         /* in zephyr\dts\arm\st\u5\stm32u595.dtsi:121 */
		};

		/* node '/soc/aes@420c0000' defined in zephyr\dts\arm\st\u5\stm32u5_crypt.dtsi:9 */
		aes: aes@420c0000 {
			compatible = "st,stm32-aes";    /* in zephyr\dts\arm\st\u5\stm32u5_crypt.dtsi:10 */
			reg = < 0x420c0000 0x400 >;     /* in zephyr\dts\arm\st\u5\stm32u5_crypt.dtsi:11 */
			clocks = < &rcc 0x8c 0x10000 >; /* in zephyr\dts\arm\st\u5\stm32u5_crypt.dtsi:12 */
			resets = < &rctl 0xc90 >;       /* in zephyr\dts\arm\st\u5\stm32u5_crypt.dtsi:13 */
			interrupts = < 0x5d 0x0 >;      /* in zephyr\dts\arm\st\u5\stm32u5_crypt.dtsi:14 */
			status = "disabled";            /* in zephyr\dts\arm\st\u5\stm32u5_crypt.dtsi:15 */
		};
	};

	/* node '/cpus' defined in zephyr\dts\arm\st\u5\stm32u5.dtsi:32 */
	cpus {
		#address-cells = < 0x1 >; /* in zephyr\dts\arm\st\u5\stm32u5.dtsi:33 */
		#size-cells = < 0x0 >;    /* in zephyr\dts\arm\st\u5\stm32u5.dtsi:34 */

		/* node '/cpus/cpu@0' defined in zephyr\dts\arm\st\u5\stm32u5.dtsi:36 */
		cpu0: cpu@0 {
			device_type = "cpu";                         /* in zephyr\dts\arm\st\u5\stm32u5.dtsi:37 */
			compatible = "arm,cortex-m33";               /* in zephyr\dts\arm\st\u5\stm32u5.dtsi:38 */
			reg = < 0x0 >;                               /* in zephyr\dts\arm\st\u5\stm32u5.dtsi:39 */
			#address-cells = < 0x1 >;                    /* in zephyr\dts\arm\st\u5\stm32u5.dtsi:40 */
			#size-cells = < 0x1 >;                       /* in zephyr\dts\arm\st\u5\stm32u5.dtsi:41 */
			cpu-power-states = < &stop0 &stop1 &stop2 >; /* in zephyr\dts\arm\st\u5\stm32u5.dtsi:42 */

			/* node '/cpus/cpu@0/mpu@e000ed90' defined in zephyr\dts\arm\st\u5\stm32u5.dtsi:44 */
			mpu: mpu@e000ed90 {
				compatible = "arm,armv8m-mpu"; /* in zephyr\dts\arm\st\u5\stm32u5.dtsi:45 */
				reg = < 0xe000ed90 0x40 >;     /* in zephyr\dts\arm\st\u5\stm32u5.dtsi:46 */
			};
		};

		/* node '/cpus/power-states' defined in zephyr\dts\arm\st\u5\stm32u5.dtsi:50 */
		power-states {

			/* node '/cpus/power-states/state0' defined in zephyr\dts\arm\st\u5\stm32u5.dtsi:51 */
			stop0: state0 {
				compatible = "zephyr,power-state";    /* in zephyr\dts\arm\st\u5\stm32u5.dtsi:52 */
				power-state-name = "suspend-to-idle"; /* in zephyr\dts\arm\st\u5\stm32u5.dtsi:53 */
				substate-id = < 0x1 >;                /* in zephyr\dts\arm\st\u5\stm32u5.dtsi:54 */
				min-residency-us = < 0x64 >;          /* in zephyr\dts\arm\st\u5\stm32u5.dtsi:55 */
				phandle = < 0x29 >;                   /* in zephyr\dts\arm\st\u5\stm32u5.dtsi:42 */
			};

			/* node '/cpus/power-states/state1' defined in zephyr\dts\arm\st\u5\stm32u5.dtsi:58 */
			stop1: state1 {
				compatible = "zephyr,power-state";    /* in zephyr\dts\arm\st\u5\stm32u5.dtsi:59 */
				power-state-name = "suspend-to-idle"; /* in zephyr\dts\arm\st\u5\stm32u5.dtsi:60 */
				substate-id = < 0x2 >;                /* in zephyr\dts\arm\st\u5\stm32u5.dtsi:61 */
				min-residency-us = < 0x1f4 >;         /* in zephyr\dts\arm\st\u5\stm32u5.dtsi:62 */
				phandle = < 0x2a >;                   /* in zephyr\dts\arm\st\u5\stm32u5.dtsi:42 */
			};

			/* node '/cpus/power-states/state2' defined in zephyr\dts\arm\st\u5\stm32u5.dtsi:65 */
			stop2: state2 {
				compatible = "zephyr,power-state";    /* in zephyr\dts\arm\st\u5\stm32u5.dtsi:66 */
				power-state-name = "suspend-to-idle"; /* in zephyr\dts\arm\st\u5\stm32u5.dtsi:67 */
				substate-id = < 0x3 >;                /* in zephyr\dts\arm\st\u5\stm32u5.dtsi:68 */
				min-residency-us = < 0x384 >;         /* in zephyr\dts\arm\st\u5\stm32u5.dtsi:69 */
				phandle = < 0x2b >;                   /* in zephyr\dts\arm\st\u5\stm32u5.dtsi:42 */
			};
		};
	};

	/* node '/memory@20000000' defined in zephyr\dts\arm\st\u5\stm32u5.dtsi:82 */
	sram0: memory@20000000 {
		compatible = "zephyr,memory-region",
		             "mmio-sram";            /* in zephyr\dts\arm\st\u5\stm32u5.dtsi:83 */
		zephyr,memory-region = "SRAM0";      /* in zephyr\dts\arm\st\u5\stm32u5.dtsi:84 */
		reg = < 0x20000000 0x270000 >;       /* in zephyr\dts\arm\st\u5\stm32u595.dtsi:14 */
	};

	/* node '/clocks' defined in zephyr\dts\arm\st\u5\stm32u5.dtsi:87 */
	clocks {

		/* node '/clocks/clk-hse' defined in zephyr\dts\arm\st\u5\stm32u5.dtsi:88 */
		clk_hse: clk-hse {
			#clock-cells = < 0x0 >;            /* in zephyr\dts\arm\st\u5\stm32u5.dtsi:89 */
			compatible = "st,stm32-hse-clock"; /* in zephyr\dts\arm\st\u5\stm32u5.dtsi:90 */
			status = "okay";                   /* in boards\nucleo_u5a5zj_q.overlay:4 */
			clock-frequency = < 0xf42400 >;    /* in boards\nucleo_u5a5zj_q.overlay:5 */
			phandle = < 0x2c >;                /* in boards\nucleo_u5a5zj_q.overlay:9 */
		};

		/* node '/clocks/clk-hsi' defined in zephyr\dts\arm\st\u5\stm32u5.dtsi:94 */
		clk_hsi: clk-hsi {
			#clock-cells = < 0x0 >;         /* in zephyr\dts\arm\st\u5\stm32u5.dtsi:95 */
			compatible = "fixed-clock";     /* in zephyr\dts\arm\st\u5\stm32u5.dtsi:96 */
			clock-frequency = < 0xf42400 >; /* in zephyr\dts\arm\st\u5\stm32u5.dtsi:97 */
			status = "disabled";            /* in zephyr\dts\arm\st\u5\stm32u5.dtsi:98 */
		};

		/* node '/clocks/clk-hsi48' defined in zephyr\dts\arm\st\u5\stm32u5.dtsi:101 */
		clk_hsi48: clk-hsi48 {
			#clock-cells = < 0x0 >;          /* in zephyr\dts\arm\st\u5\stm32u5.dtsi:102 */
			compatible = "fixed-clock";      /* in zephyr\dts\arm\st\u5\stm32u5.dtsi:103 */
			clock-frequency = < 0x2dc6c00 >; /* in zephyr\dts\arm\st\u5\stm32u5.dtsi:104 */
			status = "okay";                 /* in zephyr\boards\st\nucleo_u5a5zj_q\nucleo_u5a5zj_q-common.dtsi:60 */
		};

		/* node '/clocks/clk-msis' defined in zephyr\dts\arm\st\u5\stm32u5.dtsi:108 */
		clk_msis: clk-msis {
			#clock-cells = < 0x0 >;              /* in zephyr\dts\arm\st\u5\stm32u5.dtsi:109 */
			compatible = "st,stm32u5-msi-clock"; /* in zephyr\dts\arm\st\u5\stm32u5.dtsi:110 */
			msi-range = < 0x4 >;                 /* in zephyr\dts\arm\st\u5\stm32u5.dtsi:111 */
			status = "disabled";                 /* in zephyr\dts\arm\st\u5\stm32u5.dtsi:112 */
		};

		/* node '/clocks/clk-msik' defined in zephyr\dts\arm\st\u5\stm32u5.dtsi:115 */
		clk_msik: clk-msik {
			#clock-cells = < 0x0 >;              /* in zephyr\dts\arm\st\u5\stm32u5.dtsi:116 */
			compatible = "st,stm32u5-msi-clock"; /* in zephyr\dts\arm\st\u5\stm32u5.dtsi:117 */
			msi-range = < 0x4 >;                 /* in zephyr\dts\arm\st\u5\stm32u5.dtsi:118 */
			status = "disabled";                 /* in zephyr\dts\arm\st\u5\stm32u5.dtsi:119 */
		};

		/* node '/clocks/clk-lse' defined in zephyr\dts\arm\st\u5\stm32u5.dtsi:122 */
		clk_lse: clk-lse {
			#clock-cells = < 0x0 >;            /* in zephyr\dts\arm\st\u5\stm32u5.dtsi:123 */
			compatible = "st,stm32-lse-clock"; /* in zephyr\dts\arm\st\u5\stm32u5.dtsi:124 */
			clock-frequency = < 0x8000 >;      /* in zephyr\dts\arm\st\u5\stm32u5.dtsi:125 */
			driving-capability = < 0x2 >;      /* in zephyr\dts\arm\st\u5\stm32u5.dtsi:126 */
			status = "okay";                   /* in zephyr\boards\st\nucleo_u5a5zj_q\nucleo_u5a5zj_q-common.dtsi:70 */
		};

		/* node '/clocks/clk-lsi' defined in zephyr\dts\arm\st\u5\stm32u5.dtsi:130 */
		clk_lsi: clk-lsi {
			#clock-cells = < 0x0 >;       /* in zephyr\dts\arm\st\u5\stm32u5.dtsi:131 */
			compatible = "fixed-clock";   /* in zephyr\dts\arm\st\u5\stm32u5.dtsi:132 */
			clock-frequency = < 0x7d00 >; /* in zephyr\dts\arm\st\u5\stm32u5.dtsi:133 */
			status = "disabled";          /* in zephyr\dts\arm\st\u5\stm32u5.dtsi:134 */
		};

		/* node '/clocks/pll' defined in zephyr\dts\arm\st\u5\stm32u5.dtsi:137 */
		pll1: pll: pll {
			#clock-cells = < 0x0 >;              /* in zephyr\dts\arm\st\u5\stm32u5.dtsi:138 */
			compatible = "st,stm32u5-pll-clock"; /* in zephyr\dts\arm\st\u5\stm32u5.dtsi:139 */
			clocks = < &clk_hse >;               /* in boards\nucleo_u5a5zj_q.overlay:9 */
			div-m = < 0x4 >;                     /* in boards\nucleo_u5a5zj_q.overlay:10 */
			mul-n = < 0x50 >;                    /* in boards\nucleo_u5a5zj_q.overlay:11 */
			div-q = < 0x2 >;                     /* in boards\nucleo_u5a5zj_q.overlay:12 */
			div-r = < 0x2 >;                     /* in boards\nucleo_u5a5zj_q.overlay:13 */
			status = "okay";                     /* in boards\nucleo_u5a5zj_q.overlay:14 */
			phandle = < 0x2 >;                   /* in zephyr\boards\st\nucleo_u5a5zj_q\nucleo_u5a5zj_q-common.dtsi:84 */
		};

		/* node '/clocks/pll2' defined in zephyr\dts\arm\st\u5\stm32u5.dtsi:143 */
		pll2: pll2 {
			#clock-cells = < 0x0 >;              /* in zephyr\dts\arm\st\u5\stm32u5.dtsi:144 */
			compatible = "st,stm32u5-pll-clock"; /* in zephyr\dts\arm\st\u5\stm32u5.dtsi:145 */
			status = "disabled";                 /* in zephyr\dts\arm\st\u5\stm32u5.dtsi:146 */
		};

		/* node '/clocks/pll3' defined in zephyr\dts\arm\st\u5\stm32u5.dtsi:149 */
		pll3: pll3 {
			#clock-cells = < 0x0 >;              /* in zephyr\dts\arm\st\u5\stm32u5.dtsi:150 */
			compatible = "st,stm32u5-pll-clock"; /* in zephyr\dts\arm\st\u5\stm32u5.dtsi:151 */
			status = "disabled";                 /* in zephyr\dts\arm\st\u5\stm32u5.dtsi:152 */
		};
	};

	/* node '/mcos' defined in zephyr\dts\arm\st\u5\stm32u5.dtsi:156 */
	mcos {

		/* node '/mcos/mco1' defined in zephyr\dts\arm\st\u5\stm32u5.dtsi:157 */
		mco1: mco1 {
			compatible = "st,stm32-clock-mco"; /* in zephyr\dts\arm\st\u5\stm32u5.dtsi:158 */
			status = "disabled";               /* in zephyr\dts\arm\st\u5\stm32u5.dtsi:159 */
		};
	};

	/* node '/swj_port' defined in zephyr\dts\arm\st\u5\stm32u5.dtsi:1014 */
	swj_port: swj_port {
		compatible = "swj-connector";                                                                    /* in zephyr\dts\arm\st\u5\stm32u5.dtsi:1015 */
		pinctrl-0 = < &debug_jtms_swdio_pa13 &debug_jtck_swclk_pa14 &debug_jtdi_pa15 &debug_jtdo_swo_pb3
		              &debug_jtrst_pb4 >;                                                                /* in zephyr\dts\arm\st\u5\stm32u5.dtsi:1016 */
		pinctrl-1 = < &analog_pa13 &analog_pa14 &analog_pa15 &analog_pb3 &analog_pb4 >;                  /* in zephyr\dts\arm\st\u5\stm32u5.dtsi:1019 */
		pinctrl-names = "default",
		                "sleep";                                                                         /* in zephyr\dts\arm\st\u5\stm32u5.dtsi:1021 */
	};

	/* node '/dietemp' defined in zephyr\dts\arm\st\u5\stm32u5.dtsi:1024 */
	die_temp: dietemp {
		compatible = "st,stm32-temp-cal"; /* in zephyr\dts\arm\st\u5\stm32u5.dtsi:1025 */
		ts-cal1-addr = < 0xbfa0710 >;     /* in zephyr\dts\arm\st\u5\stm32u5.dtsi:1026 */
		ts-cal2-addr = < 0xbfa0742 >;     /* in zephyr\dts\arm\st\u5\stm32u5.dtsi:1027 */
		ts-cal1-temp = < 0x1e >;          /* in zephyr\dts\arm\st\u5\stm32u5.dtsi:1028 */
		ts-cal2-temp = < 0x82 >;          /* in zephyr\dts\arm\st\u5\stm32u5.dtsi:1029 */
		ts-cal-vrefanalog = < 0xbb8 >;    /* in zephyr\dts\arm\st\u5\stm32u5.dtsi:1030 */
		ts-cal-resolution = < 0xe >;      /* in zephyr\dts\arm\st\u5\stm32u5.dtsi:1031 */
		io-channels = < &adc1 0x13 >;     /* in zephyr\dts\arm\st\u5\stm32u5.dtsi:1032 */
		status = "disabled";              /* in zephyr\dts\arm\st\u5\stm32u5.dtsi:1033 */
	};

	/* node '/vref_1' defined in zephyr\dts\arm\st\u5\stm32u5.dtsi:1036 */
	vref1: vref_1 {
		compatible = "st,stm32-vref";     /* in zephyr\dts\arm\st\u5\stm32u5.dtsi:1037 */
		vrefint-cal-addr = < 0xbfa07a5 >; /* in zephyr\dts\arm\st\u5\stm32u5.dtsi:1038 */
		vrefint-cal-mv = < 0xbb8 >;       /* in zephyr\dts\arm\st\u5\stm32u5.dtsi:1039 */
		vrefint-cal-resolution = < 0xe >; /* in zephyr\dts\arm\st\u5\stm32u5.dtsi:1040 */
		io-channels = < &adc1 0x0 >;      /* in zephyr\dts\arm\st\u5\stm32u5.dtsi:1041 */
		status = "okay";                  /* in zephyr\boards\st\nucleo_u5a5zj_q\nucleo_u5a5zj_q-common.dtsi:194 */
	};

	/* node '/vref_4' defined in zephyr\dts\arm\st\u5\stm32u5.dtsi:1045 */
	vref4: vref_4 {
		compatible = "st,stm32-vref";     /* in zephyr\dts\arm\st\u5\stm32u5.dtsi:1046 */
		vrefint-cal-addr = < 0xbfa07a5 >; /* in zephyr\dts\arm\st\u5\stm32u5.dtsi:1047 */
		vrefint-cal-mv = < 0xbb8 >;       /* in zephyr\dts\arm\st\u5\stm32u5.dtsi:1048 */
		vrefint-cal-resolution = < 0xe >; /* in zephyr\dts\arm\st\u5\stm32u5.dtsi:1049 */
		io-channels = < &adc4 0x0 >;      /* in zephyr\dts\arm\st\u5\stm32u5.dtsi:1050 */
		status = "disabled";              /* in zephyr\dts\arm\st\u5\stm32u5.dtsi:1051 */
	};

	/* node '/vbat_1' defined in zephyr\dts\arm\st\u5\stm32u5.dtsi:1054 */
	vbat1: vbat_1 {
		compatible = "st,stm32-vbat"; /* in zephyr\dts\arm\st\u5\stm32u5.dtsi:1055 */
		ratio = < 0x4 >;              /* in zephyr\dts\arm\st\u5\stm32u5.dtsi:1056 */
		io-channels = < &adc1 0x12 >; /* in zephyr\dts\arm\st\u5\stm32u5.dtsi:1057 */
		status = "disabled";          /* in zephyr\dts\arm\st\u5\stm32u5.dtsi:1058 */
	};

	/* node '/vbat_4' defined in zephyr\dts\arm\st\u5\stm32u5.dtsi:1061 */
	vbat4: vbat_4 {
		compatible = "st,stm32-vbat"; /* in zephyr\dts\arm\st\u5\stm32u5.dtsi:1062 */
		ratio = < 0x4 >;              /* in zephyr\dts\arm\st\u5\stm32u5.dtsi:1063 */
		io-channels = < &adc4 0xe >;  /* in zephyr\dts\arm\st\u5\stm32u5.dtsi:1064 */
		status = "okay";              /* in zephyr\boards\st\nucleo_u5a5zj_q\nucleo_u5a5zj_q-common.dtsi:198 */
	};

	/* node '/smbus1' defined in zephyr\dts\arm\st\u5\stm32u5.dtsi:1068 */
	smbus1: smbus1 {
		compatible = "st,stm32-smbus"; /* in zephyr\dts\arm\st\u5\stm32u5.dtsi:1069 */
		#address-cells = < 0x1 >;      /* in zephyr\dts\arm\st\u5\stm32u5.dtsi:1070 */
		#size-cells = < 0x0 >;         /* in zephyr\dts\arm\st\u5\stm32u5.dtsi:1071 */
		i2c = < &i2c1 >;               /* in zephyr\dts\arm\st\u5\stm32u5.dtsi:1072 */
		status = "disabled";           /* in zephyr\dts\arm\st\u5\stm32u5.dtsi:1073 */
	};

	/* node '/smbus2' defined in zephyr\dts\arm\st\u5\stm32u5.dtsi:1076 */
	smbus2: smbus2 {
		compatible = "st,stm32-smbus"; /* in zephyr\dts\arm\st\u5\stm32u5.dtsi:1077 */
		#address-cells = < 0x1 >;      /* in zephyr\dts\arm\st\u5\stm32u5.dtsi:1078 */
		#size-cells = < 0x0 >;         /* in zephyr\dts\arm\st\u5\stm32u5.dtsi:1079 */
		i2c = < &i2c2 >;               /* in zephyr\dts\arm\st\u5\stm32u5.dtsi:1080 */
		status = "disabled";           /* in zephyr\dts\arm\st\u5\stm32u5.dtsi:1081 */
	};

	/* node '/smbus3' defined in zephyr\dts\arm\st\u5\stm32u5.dtsi:1084 */
	smbus3: smbus3 {
		compatible = "st,stm32-smbus"; /* in zephyr\dts\arm\st\u5\stm32u5.dtsi:1085 */
		#address-cells = < 0x1 >;      /* in zephyr\dts\arm\st\u5\stm32u5.dtsi:1086 */
		#size-cells = < 0x0 >;         /* in zephyr\dts\arm\st\u5\stm32u5.dtsi:1087 */
		i2c = < &i2c3 >;               /* in zephyr\dts\arm\st\u5\stm32u5.dtsi:1088 */
		status = "disabled";           /* in zephyr\dts\arm\st\u5\stm32u5.dtsi:1089 */
	};

	/* node '/smbus4' defined in zephyr\dts\arm\st\u5\stm32u5.dtsi:1092 */
	smbus4: smbus4 {
		compatible = "st,stm32-smbus"; /* in zephyr\dts\arm\st\u5\stm32u5.dtsi:1093 */
		#address-cells = < 0x1 >;      /* in zephyr\dts\arm\st\u5\stm32u5.dtsi:1094 */
		#size-cells = < 0x0 >;         /* in zephyr\dts\arm\st\u5\stm32u5.dtsi:1095 */
		i2c = < &i2c4 >;               /* in zephyr\dts\arm\st\u5\stm32u5.dtsi:1096 */
		status = "disabled";           /* in zephyr\dts\arm\st\u5\stm32u5.dtsi:1097 */
	};

	/* node '/otghs_phy' defined in zephyr\dts\arm\st\u5\stm32u5_usbotg_hs.dtsi:26 */
	otghs_phy: otghs_phy {
		compatible = "st,stm32u5-otghs-phy";             /* in zephyr\dts\arm\st\u5\stm32u5_usbotg_hs.dtsi:27 */
		clocks = < &rcc 0x8c 0x8000 >,
		         < &rcc 0x4 0x3e00e4 >;                  /* in zephyr\dts\arm\st\u5\stm32u5_usbotg_hs.dtsi:28 */
		#phy-cells = < 0x0 >;                            /* in zephyr\dts\arm\st\u5\stm32u5_usbotg_hs.dtsi:30 */
		clock-reference = "SYSCFG_OTG_HS_PHY_CLK_16MHz"; /* in zephyr\boards\st\nucleo_u5a5zj_q\nucleo_u5a5zj_q.dts:87 */
		status = "okay";                                 /* in zephyr\boards\st\nucleo_u5a5zj_q\nucleo_u5a5zj_q.dts:88 */
		phandle = < 0x26 >;                              /* in zephyr\dts\arm\st\u5\stm32u5_usbotg_hs.dtsi:21 */
	};

	/* node '/memory@28000000' defined in zephyr\dts\arm\st\u5\stm32u595.dtsi:17 */
	sram1: memory@28000000 {
		reg = < 0x28000000 0x4000 >; /* in zephyr\dts\arm\st\u5\stm32u595.dtsi:19 */
	};

	/* node '/smbus5' defined in zephyr\dts\arm\st\u5\stm32u595.dtsi:125 */
	smbus5: smbus5 {
		compatible = "st,stm32-smbus"; /* in zephyr\dts\arm\st\u5\stm32u595.dtsi:126 */
		#address-cells = < 0x1 >;      /* in zephyr\dts\arm\st\u5\stm32u595.dtsi:127 */
		#size-cells = < 0x0 >;         /* in zephyr\dts\arm\st\u5\stm32u595.dtsi:128 */
		i2c = < &i2c5 >;               /* in zephyr\dts\arm\st\u5\stm32u595.dtsi:129 */
		status = "disabled";           /* in zephyr\dts\arm\st\u5\stm32u595.dtsi:130 */
	};

	/* node '/smbus6' defined in zephyr\dts\arm\st\u5\stm32u595.dtsi:133 */
	smbus6: smbus6 {
		compatible = "st,stm32-smbus"; /* in zephyr\dts\arm\st\u5\stm32u595.dtsi:134 */
		#address-cells = < 0x1 >;      /* in zephyr\dts\arm\st\u5\stm32u595.dtsi:135 */
		#size-cells = < 0x0 >;         /* in zephyr\dts\arm\st\u5\stm32u595.dtsi:136 */
		i2c = < &i2c6 >;               /* in zephyr\dts\arm\st\u5\stm32u595.dtsi:137 */
		status = "disabled";           /* in zephyr\dts\arm\st\u5\stm32u595.dtsi:138 */
	};

	/* node '/connector' defined in zephyr\boards\st\nucleo_u5a5zj_q\arduino_r3_connector.dtsi:10 */
	arduino_header: connector {
		compatible = "arduino-header-r3";          /* in zephyr\boards\st\nucleo_u5a5zj_q\arduino_r3_connector.dtsi:11 */
		#gpio-cells = < 0x2 >;                     /* in zephyr\boards\st\nucleo_u5a5zj_q\arduino_r3_connector.dtsi:12 */
		gpio-map-mask = < 0xffffffff 0xffffffc0 >; /* in zephyr\boards\st\nucleo_u5a5zj_q\arduino_r3_connector.dtsi:13 */
		gpio-map-pass-thru = < 0x0 0x3f >;         /* in zephyr\boards\st\nucleo_u5a5zj_q\arduino_r3_connector.dtsi:14 */
		gpio-map = < 0x0 0x0 &gpioa 0x3 0x0 >,
		           < 0x1 0x0 &gpioa 0x2 0x0 >,
		           < 0x2 0x0 &gpioc 0x3 0x0 >,
		           < 0x3 0x0 &gpiob 0x0 0x0 >,
		           < 0x4 0x0 &gpioc 0x1 0x0 >,
		           < 0x5 0x0 &gpioc 0x0 0x0 >,
		           < 0x6 0x0 &gpiog 0x8 0x0 >,
		           < 0x7 0x0 &gpiog 0x7 0x0 >,
		           < 0x8 0x0 &gpiof 0xf 0x0 >,
		           < 0x9 0x0 &gpioe 0xd 0x0 >,
		           < 0xa 0x0 &gpiof 0xe 0x0 >,
		           < 0xb 0x0 &gpioe 0xb 0x0 >,
		           < 0xc 0x0 &gpioe 0x9 0x0 >,
		           < 0xd 0x0 &gpiof 0xd 0x0 >,
		           < 0xe 0x0 &gpiof 0xc 0x0 >,
		           < 0xf 0x0 &gpiod 0xf 0x0 >,
		           < 0x10 0x0 &gpiod 0xe 0x0 >,
		           < 0x11 0x0 &gpioa 0x7 0x0 >,
		           < 0x12 0x0 &gpioa 0x6 0x0 >,
		           < 0x13 0x0 &gpioa 0x5 0x0 >,
		           < 0x14 0x0 &gpiob 0x9 0x0 >,
		           < 0x15 0x0 &gpiob 0x8 0x0 >;    /* in zephyr\boards\st\nucleo_u5a5zj_q\arduino_r3_connector.dtsi:15 */
	};

	/* node '/leds' defined in zephyr\boards\st\nucleo_u5a5zj_q\nucleo_u5a5zj_q-common.dtsi:13 */
	leds: leds {
		compatible = "gpio-leds"; /* in zephyr\boards\st\nucleo_u5a5zj_q\nucleo_u5a5zj_q-common.dtsi:14 */

		/* node '/leds/led_1' defined in zephyr\boards\st\nucleo_u5a5zj_q\nucleo_u5a5zj_q-common.dtsi:16 */
		green_led_1: led_1 {
			gpios = < &gpioc 0x7 0x0 >; /* in zephyr\boards\st\nucleo_u5a5zj_q\nucleo_u5a5zj_q-common.dtsi:17 */
			label = "User LD1";         /* in zephyr\boards\st\nucleo_u5a5zj_q\nucleo_u5a5zj_q-common.dtsi:18 */
		};

		/* node '/leds/led_2' defined in zephyr\boards\st\nucleo_u5a5zj_q\nucleo_u5a5zj_q-common.dtsi:21 */
		blue_led_1: led_2 {
			gpios = < &gpiob 0x7 0x0 >; /* in zephyr\boards\st\nucleo_u5a5zj_q\nucleo_u5a5zj_q-common.dtsi:22 */
			label = "User LD2";         /* in zephyr\boards\st\nucleo_u5a5zj_q\nucleo_u5a5zj_q-common.dtsi:23 */
		};

		/* node '/leds/led_3' defined in zephyr\boards\st\nucleo_u5a5zj_q\nucleo_u5a5zj_q-common.dtsi:26 */
		red_led_1: led_3 {
			gpios = < &gpiog 0x2 0x0 >; /* in zephyr\boards\st\nucleo_u5a5zj_q\nucleo_u5a5zj_q-common.dtsi:27 */
			label = "User LD3";         /* in zephyr\boards\st\nucleo_u5a5zj_q\nucleo_u5a5zj_q-common.dtsi:28 */
		};
	};

	/* node '/gpio_keys' defined in zephyr\boards\st\nucleo_u5a5zj_q\nucleo_u5a5zj_q-common.dtsi:32 */
	gpio_keys {
		compatible = "gpio-keys"; /* in zephyr\boards\st\nucleo_u5a5zj_q\nucleo_u5a5zj_q-common.dtsi:33 */

		/* node '/gpio_keys/button' defined in zephyr\boards\st\nucleo_u5a5zj_q\nucleo_u5a5zj_q-common.dtsi:35 */
		user_button: button {
			label = "User";             /* in zephyr\boards\st\nucleo_u5a5zj_q\nucleo_u5a5zj_q-common.dtsi:36 */
			gpios = < &gpioc 0xd 0x0 >; /* in zephyr\boards\st\nucleo_u5a5zj_q\nucleo_u5a5zj_q-common.dtsi:37 */
			zephyr,code = < 0xb >;      /* in zephyr\boards\st\nucleo_u5a5zj_q\nucleo_u5a5zj_q-common.dtsi:38 */
		};
	};

	/* node '/pwmleds' defined in zephyr\boards\st\nucleo_u5a5zj_q\nucleo_u5a5zj_q-common.dtsi:42 */
	pwmleds: pwmleds {
		compatible = "pwm-leds"; /* in zephyr\boards\st\nucleo_u5a5zj_q\nucleo_u5a5zj_q-common.dtsi:43 */
		status = "disabled";     /* in zephyr\boards\st\nucleo_u5a5zj_q\nucleo_u5a5zj_q-common.dtsi:45 */

		/* node '/pwmleds/green_led_1' defined in zephyr\boards\st\nucleo_u5a5zj_q\nucleo_u5a5zj_q-common.dtsi:47 */
		pwm_led_1: green_led_1 {
			pwms = < &pwm3 0x2 0x1312d00 0x0 >; /* in zephyr\boards\st\nucleo_u5a5zj_q\nucleo_u5a5zj_q-common.dtsi:48 */
			label = "green led";                /* in zephyr\boards\st\nucleo_u5a5zj_q\nucleo_u5a5zj_q-common.dtsi:49 */
		};

		/* node '/pwmleds/blue_led_1' defined in zephyr\boards\st\nucleo_u5a5zj_q\nucleo_u5a5zj_q-common.dtsi:52 */
		pwm_led_2: blue_led_1 {
			pwms = < &pwm4 0x2 0x1312d00 0x0 >; /* in zephyr\boards\st\nucleo_u5a5zj_q\nucleo_u5a5zj_q-common.dtsi:53 */
			label = "blue led";                 /* in zephyr\boards\st\nucleo_u5a5zj_q\nucleo_u5a5zj_q-common.dtsi:54 */
		};
	};
};
